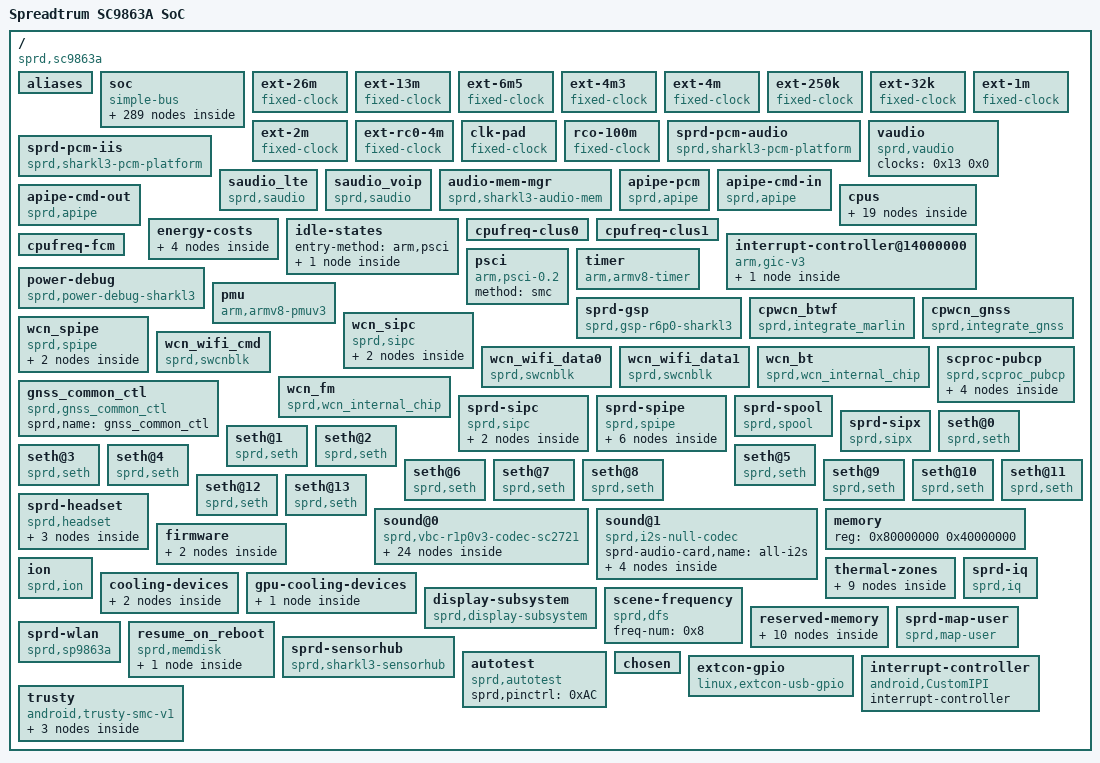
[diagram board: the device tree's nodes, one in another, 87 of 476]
/dts-v1/;
// version: 17
// last_comp_version: 16
// boot_cpuid_phys: 0x0

/ {
    interrupt-parent = <0x1>;
    #address-cells = <0x1>;
    #size-cells = <0x1>;
    cpuinfo_hardware = "Unisoc SC9863a";
    model = "Spreadtrum SC9863A SoC";
    compatible = "sprd,sc9863a";
    sprd,sc-id = "sp9863a 1000 1000";
    aliases {
        i2c0 = "/soc/ap-apb/i2c@70500000";
        i2c1 = "/soc/ap-apb/i2c@70600000";
        i2c2 = "/soc/ap-apb/i2c@70700000";
        i2c3 = "/soc/ap-apb/i2c@70800000";
        i2c4 = "/soc/ap-apb/i2c@70900000";
        i2c5 = "/soc/ap-apb/i2c@71500000";
        i2c6 = "/soc/ap-apb/i2c@71600000";
        i2c7 = "/soc/aon/i2c@40080000";
        spi0 = "/soc/ap-apb/spi@70a00000";
        spi1 = "/soc/ap-apb/spi@70b00000";
        spi2 = "/soc/ap-apb/spi@70c00000";
        spi3 = "/soc/ap-apb/spi@71400000";
        seth0 = "/seth@0";
        seth1 = "/seth@1";
        seth2 = "/seth@2";
        seth3 = "/seth@3";
        seth4 = "/seth@4";
        seth5 = "/seth@5";
        seth6 = "/seth@6";
        seth7 = "/seth@7";
        seth8 = "/seth@8";
        seth9 = "/seth@9";
        seth10 = "/seth@10";
        seth11 = "/seth@11";
        seth12 = "/seth@12";
        seth13 = "/seth@13";
        cooling-device0 = "/cooling-devices/cluster0-cooling";
        cooling-device1 = "/cooling-devices/cluster1-cooling";
        gpu-cooling0 = "/gpu-cooling-devices/gpu-cooling0";
        thm-sensor11 = "/thermal-zones/cpu-thmzone";
        serial0 = "/soc/ap-apb/serial@70000000";
        serial1 = "/soc/ap-apb/serial@70100000";
    };
    soc {
        compatible = "simple-bus";
        #address-cells = <0x1>;
        #size-cells = <0x1>;
        ranges;
        phandle = <0xAF>;
        modem-dbg-log@1000c000 {
            compatible = "sprd,dbg-log-sharkl3";
            reg = <0x1000C000 0x4000>;
            sprd,syscon-aon-apb = <0x2>;
            sprd,syscon-dsi-apb = <0x3>;
            sprd,syscon-pll-apb = <0x4>;
            sprd,ch-name = "TRAINING", "WTL", "MDAR", "TPIU", "DBUS", "WCN";
            sprd,ch-index = <0xF 0x1 0x0 0x2 0x3 0x4>;
            sprd,dcfix;
            sprd,mm;
            status = "okay";
            clock-names = "serdes_eb", "src0", "src1", "src2";
            clocks = <0x5 0x68 0x6 0x0 0x6 0x18 0x6 0x14>;
            phandle = <0xB0>;
        };
        syscon@20e00000 {
            compatible = "syscon";
            #syscon-cells = <0x2>;
            reg = <0x20E00000 0x10000>;
            phandle = <0xE>;
        };
        syscon@300e0000 {
            compatible = "syscon";
            #syscon-cells = <0x2>;
            reg = <0x300E0000 0x10000>;
            phandle = <0x8D>;
        };
        syscon@300f0000 {
            compatible = "syscon";
            #syscon-cells = <0x2>;
            reg = <0x300F0000 0x10000>;
            phandle = <0x4F>;
        };
        mailbox@400a0000 {
            compatible = "sprd,mailbox";
            reg = <0x400A0000 0x8000 0x400A8000 0x8000>;
            syscons = <0x2 0x4 0x200000>;
            syscon-names = "clk";
            interrupts = <0x0 0x44 0x4 0x0 0x45 0x4 0x0 0x77 0x4>;
            sprd,sensor = <0x7>;
            sprd,core-cnt = <0x8>;
            sprd,version = <0x102>;
            phandle = <0xB1>;
        };
        syscon@40200000 {
            compatible = "syscon";
            #syscon-cells = <0x2>;
            reg = <0x40200000 0x10000>;
            phandle = <0xB2>;
        };
        syscon@402b0000 {
            compatible = "syscon";
            #syscon-cells = <0x2>;
            reg = <0x402B0000 0x10000>;
            phandle = <0x7>;
        };
        power-domain@402b0058 {
            compatible = "sprd,sharkl3-disp-domain";
            reg = <0x402B0058 0x20>;
            syscons = <0x7 0x58 0x2000000>;
            syscon-names = "power";
            #power-domain-cells = <0x0>;
            phandle = <0x3B>;
        };
        syscon@402e0000 {
            compatible = "syscon";
            #syscon-cells = <0x2>;
            reg = <0x402E0000 0x10000>;
            phandle = <0x2>;
        };
        syscon@40350000 {
            compatible = "syscon";
            #syscon-cells = <0x2>;
            reg = <0x40350000 0x3000>;
            phandle = <0x3>;
        };
        syscon@40353000 {
            compatible = "syscon";
            #syscon-cells = <0x2>;
            reg = <0x40353000 0x6000>;
            phandle = <0x4>;
        };
        syscon@40359000 {
            compatible = "syscon";
            #syscon-cells = <0x2>;
            reg = <0x40359000 0x3000>;
            phandle = <0xF>;
        };
        syscon@4035c000 {
            compatible = "syscon";
            #syscon-cells = <0x2>;
            reg = <0x4035C000 0x3000>;
            phandle = <0x51>;
        };
        syscon@40363000 {
            compatible = "syscon";
            #syscon-cells = <0x2>;
            reg = <0x40363000 0x3000>;
            phandle = <0x17>;
        };
        syscon@40366000 {
            compatible = "syscon";
            #syscon-cells = <0x2>;
            reg = <0x40366000 0x3000>;
            phandle = <0x8E>;
        };
        syscon@403a0000 {
            compatible = "syscon";
            #syscon-cells = <0x2>;
            reg = <0x403A0000 0x10000>;
            phandle = <0x8F>;
        };
        syscon@60800000 {
            compatible = "syscon";
            #syscon-cells = <0x2>;
            reg = <0x60800000 0x10000>;
            phandle = <0x47>;
        };
        syscon@62000000 {
            compatible = "syscon";
            #syscon-cells = <0x2>;
            reg = <0x62000000 0x10000>;
            phandle = <0x3E>;
        };
        syscon@71300000 {
            compatible = "syscon";
            #syscon-cells = <0x2>;
            reg = <0x71300000 0x40000>;
            phandle = <0xB>;
        };
        syscon@40500000 {
            compatible = "syscon";
            #syscon-cells = <0x2>;
            reg = <0x40500000 0x10000>;
            phandle = <0x86>;
        };
        syscon@40510000 {
            compatible = "syscon";
            #syscon-cells = <0x2>;
            reg = <0x40510000 0x10000>;
            phandle = <0x87>;
        };
        syscon@40520000 {
            compatible = "syscon";
            #syscon-cells = <0x2>;
            reg = <0x40520000 0x10000>;
            phandle = <0x88>;
        };
        syscon@40530000 {
            compatible = "syscon";
            #syscon-cells = <0x2>;
            reg = <0x40530000 0x10000>;
            phandle = <0x89>;
        };
        syscon@40540000 {
            compatible = "syscon";
            #syscon-cells = <0x2>;
            reg = <0x40540000 0x10000>;
            phandle = <0x8A>;
        };
        syscon@40550000 {
            compatible = "syscon";
            #syscon-cells = <0x2>;
            reg = <0x40550000 0x10000>;
            phandle = <0x8B>;
        };
        ap-apb {
            compatible = "simple-bus";
            #address-cells = <0x1>;
            #size-cells = <0x1>;
            ranges;
            serial@70000000 {
                compatible = "sprd,sc9863-uart", "sprd,sc9836-uart";
                reg = <0x70000000 0x100>;
                interrupts = <0x0 0x2 0x4>;
                clock-names = "enable", "uart", "source";
                clocks = <0x8 0xC 0x9 0x9 0xA>;
                status = "okay";
                phandle = <0xB3>;
            };
            serial@70100000 {
                compatible = "sprd,sc9863-uart", "sprd,sc9836-uart";
                reg = <0x70100000 0x100>;
                interrupts = <0x0 0x3 0x4>;
                clock-names = "enable", "uart", "source";
                clocks = <0x8 0xD 0x9 0xA 0xA>;
                status = "okay";
                phandle = <0xB4>;
            };
            serial@70200000 {
                compatible = "sprd,sc9863-uart", "sprd,sc9836-uart";
                reg = <0x70200000 0x100>;
                interrupts = <0x0 0x4 0x4>;
                clock-names = "enable", "uart", "source";
                clocks = <0x8 0xE 0x9 0xB 0xA>;
                status = "disabled";
                phandle = <0xB5>;
            };
            serial@70300000 {
                compatible = "sprd,sc9863-uart", "sprd,sc9836-uart";
                reg = <0x70300000 0x100>;
                interrupts = <0x0 0x5 0x4>;
                clock-names = "enable", "uart", "source";
                clocks = <0x8 0xF 0x9 0xC 0xA>;
                status = "disabled";
                phandle = <0xB6>;
            };
            serial@70400000 {
                compatible = "sprd,sc9863-uart", "sprd,sc9836-uart";
                reg = <0x70400000 0x100>;
                interrupts = <0x0 0x6 0x4>;
                clock-names = "enable", "uart", "source";
                clocks = <0x8 0x10 0x9 0xD 0xA>;
                status = "disabled";
                phandle = <0xB7>;
            };
            i2c@70500000 {
                compatible = "sprd,sharkl3-i2c";
                reg = <0x70500000 0x1000>;
                interrupts = <0x0 0xB 0x4>;
                clock-names = "enable", "i2c", "source";
                clock-frequency = <0x186A0>;
                #address-cells = <0x1>;
                #size-cells = <0x0>;
                status = "disabled";
                clocks = <0x8 0x7 0x9 0xE 0xA>;
                phandle = <0xB8>;
            };
            i2c@70600000 {
                compatible = "sprd,sharkl3-i2c";
                reg = <0x70600000 0x1000>;
                interrupts = <0x0 0xC 0x4>;
                clock-names = "enable", "i2c", "source";
                clock-frequency = <0x186A0>;
                #address-cells = <0x1>;
                #size-cells = <0x0>;
                status = "disabled";
                clocks = <0x8 0x8 0x9 0xF 0xA>;
                phandle = <0xB9>;
            };
            i2c@70700000 {
                compatible = "sprd,sharkl3-i2c";
                reg = <0x70700000 0x1000>;
                interrupts = <0x0 0xD 0x4>;
                clock-names = "enable", "i2c", "source";
                clock-frequency = <0x186A0>;
                #address-cells = <0x1>;
                #size-cells = <0x0>;
                status = "disabled";
                clocks = <0x8 0x9 0x9 0x10 0xA>;
                phandle = <0xBA>;
            };
            i2c@70800000 {
                compatible = "sprd,sharkl3-i2c";
                reg = <0x70800000 0x1000>;
                interrupts = <0x0 0xE 0x4>;
                clock-names = "enable", "i2c", "source";
                clock-frequency = <0x61A80>;
                #address-cells = <0x1>;
                #size-cells = <0x0>;
                status = "disabled";
                clocks = <0x8 0xA 0x9 0x11 0xA>;
                phandle = <0xBB>;
            };
            i2c@70900000 {
                compatible = "sprd,sharkl3-i2c";
                reg = <0x70900000 0x1000>;
                interrupts = <0x0 0xF 0x4>;
                clock-names = "enable", "i2c", "source";
                clock-frequency = <0x186A0>;
                #address-cells = <0x1>;
                #size-cells = <0x0>;
                status = "disabled";
                clocks = <0x8 0xB 0x9 0x12 0xA>;
                phandle = <0xBC>;
            };
            spi@70a00000 {
                compatible = "sprd,sc9863-spi";
                reg = <0x70A00000 0x1000>;
                interrupts = <0x0 0x7 0x4>;
                #address-cells = <0x1>;
                #size-cells = <0x0>;
                status = "okay";
                clock-names = "enable", "spi", "source";
                clocks = <0x8 0x4 0x9 0x15 0x6 0x3>;
                phandle = <0xBD>;
            };
            spi@70b00000 {
                compatible = "sprd,sc9863-spi";
                reg = <0x70B00000 0x1000>;
                interrupts = <0x0 0x8 0x4>;
                #address-cells = <0x1>;
                #size-cells = <0x0>;
                status = "disabled";
                clock-names = "enable", "spi", "source";
                clocks = <0x8 0x5 0x9 0x16 0x6 0x3>;
                phandle = <0xBE>;
            };
            spi@70c00000 {
                compatible = "sprd,sc9863-spi";
                reg = <0x70C00000 0x1000>;
                interrupts = <0x0 0x9 0x4>;
                #address-cells = <0x1>;
                #size-cells = <0x0>;
                status = "disabled";
                clock-names = "enable", "spi", "source";
                clocks = <0x8 0x6 0x9 0x17 0x6 0x3>;
                phandle = <0xBF>;
            };
            i2s@70d00000 {
                compatible = "sprd,i2s";
                reg = <0x70D00000 0x100000>;
                sprd,dai_name = "i2s_bt_sco0";
                sprd,hw_port = <0x0>;
                sprd,syscon-ap-apb = <0xB>;
                #sound-dai-cells = <0x0>;
                status = "okay";
                clock-names = "clk_iis0", "clk_twpll_128m", "clk_twpll_153m6";
                clocks = <0x9 0x19 0x6 0xA 0x6 0xF>;
                sprd,config_type = "pcm";
                sprd,slave_timeout = <0xF11>;
                sprd,_hw_port = <0x0>;
                sprd,fs = <0x1F40>;
                sprd,bus_type = <0x1>;
                sprd,rtx_mode = <0x3>;
                sprd,byte_per_chan = <0x1>;
                sprd,slave_mode = <0x0>;
                sprd,lsb = <0x0>;
                sprd,lrck = <0x0>;
                sprd,low_for_left = <0x1>;
                sprd,clk_inv = <0x0>;
                sprd,pcm_short_frame = <0x1>;
                sprd,pcm_slot = <0x1>;
                sprd,pcm_cycle = <0x1>;
                sprd,tx_watermark = <0xC>;
                sprd,rx_watermark = <0x14>;
                phandle = <0xA2>;
            };
            spi@71400000 {
                compatible = "sprd,sc9863-spi";
                reg = <0x71400000 0x1000>;
                interrupts = <0x0 0x13 0x4>;
                #address-cells = <0x1>;
                #size-cells = <0x0>;
                status = "disabled";
                clock-names = "enable", "spi", "source";
                clocks = <0x8 0x12 0x9 0x18 0x6 0x3>;
                phandle = <0xC0>;
            };
            i2c@71500000 {
                compatible = "sprd,sharkl3-i2c";
                reg = <0x71500000 0x1000>;
                interrupts = <0x0 0x74 0x4>;
                clock-names = "enable", "i2c", "source";
                clock-frequency = <0x186A0>;
                #address-cells = <0x1>;
                #size-cells = <0x0>;
                status = "disabled";
                clocks = <0x8 0x13 0x9 0x13 0xA>;
                phandle = <0xC1>;
            };
            i2c@71600000 {
                compatible = "sprd,sharkl3-i2c";
                reg = <0x71600000 0x1000>;
                interrupts = <0x0 0x75 0x4>;
                clock-names = "enable", "i2c", "source";
                clock-frequency = <0x186A0>;
                #address-cells = <0x1>;
                #size-cells = <0x0>;
                status = "disabled";
                clocks = <0x8 0x14 0x9 0x14 0xA>;
                phandle = <0xC2>;
            };
        };
        ap-ahb {
            compatible = "simple-bus";
            #address-cells = <0x1>;
            #size-cells = <0x1>;
            ranges;
            dma-controller@20100000 {
                compatible = "sprd,sharkl3-dma";
                reg = <0x20100000 0x4000>;
                interrupts = <0x0 0x32 0x4>;
                #dma-cells = <0x1>;
                #dma-channels = <0x1C>;
                clock-names = "enable";
                clocks = <0xC 0x1>;
                phandle = <0x77>;
            };
            usb@20200000 {
                compatible = "sprd,sharkl3-musb";
                reg = <0x20200000 0x2000>;
                interrupts = <0x0 0x37 0x4>;
                interrupt-names = "mc";
                clocks = <0xC 0x0>;
                clock-names = "core_clk";
                phy-type = "usb20_sprd_phy";
                usb-phy = <0xD>;
                phy-names = "usb";
                dr-mode = "peripheral";
                phandle = <0xC3>;
            };
            hsphy@20e00000 {
                compatible = "sprd,sharkl3-phy";
                reg = <0x20E00000 0x3030>;
                reg-names = "phy_glb_regs";
                sprd,syscon-enable = <0x2>;
                sprd,syscon-apahb = <0xE>;
                sprd,syscon-anag4 = <0xF>;
                sprd,vdd-voltage = <0x325AA0>;
                #phy-cells = <0x0>;
                vdd-supply = <0x10>;
                extcon = <0x11>;
                phandle = <0xD>;
            };
            sdio@20600000 {
                compatible = "sprd,sdhc-r11p1";
                reg = <0x20600000 0x1000>;
                interrupts = <0x0 0x3C 0x4>;
                status = "okay";
                clock-names = "sdio_clk", "sdio_clk_source", "sdio_ahb_enable";
                clocks = <0x12 0x21 0x13 0x2 0xC 0x7>;
                sprd,hs400es-dly = <0x55 0x7F 0x38 0x38>;
                sprd,hs400-dly = <0x55 0xD3 0x35 0x35>;
                sprd,hs200-dly = <0x7F 0xCD 0xCD 0xCD>;
                sprd,ddr52-dly = <0x32 0x23 0x18 0x18>;
                vmmc-supply = <0x14>;
                voltage-ranges = <0xBB8 0xBB8>;
                bus-width = <0x8>;
                non-removable;
                cap-mmc-hw-reset;
                mmc-hs400-enhanced-strobe;
                mmc-hs400-1_8v;
                mmc-hs200-1_8v;
                mmc-ddr-1_8v;
                sprd,name = "sdio_emmc";
                sprd,sdio-adma;
                no-sdio;
                no-sd;
                phandle = <0xC4>;
            };
            sdio@20300000 {
                compatible = "sprd,sdhc-r11p1";
                reg = <0x20300000 0x1000>;
                interrupts = <0x0 0x39 0x4>;
                status = "okay";
                clock-names = "sdio_clk", "sdio_clk_source", "sdio_ahb_enable";
                clocks = <0x12 0x1E 0x13 0x2 0xC 0x4>;
                sprd,sdr104-dly = <0x7F 0xD1 0xD1 0xD1>;
                sprd,sdr50-dly = <0x7F 0xFF 0xFF 0xFF>;
                sprd,sdhs-dly = <0x7F 0x23 0x22 0x22>;
                vmmc-supply = <0x15>;
                vqmmc-supply = <0x16>;
                voltage-ranges = <0xBB8 0xBB8>;
                bus-width = <0x4>;
                sd-uhs-sdr104;
                sd-uhs-sdr50;
                sprd,name = "sdio_sd";
                sprd,sdio-adma;
                no-sdio;
                no-mmc;
                phandle = <0xC5>;
            };
        };
        aon {
            compatible = "simple-bus";
            #address-cells = <0x1>;
            #size-cells = <0x1>;
            ranges;
            audio-codec@40000000 {
                compatible = "sprd,sharkl3-audio-codec";
                reg = <0x40000000 0x2000>;
                interrupts = <0x0 0x14 0x0>;
                sprd,syscon-aon-apb = <0x2>;
                sprd,anlg-phy-g-syscon = <0x17>;
                phandle = <0x39>;
            };
            vbc@40020000 {
                compatible = "sprd,vbc-r1p0v3";
                #sound-dai-cells = <0x1>;
                reg = <0x40020000 0x10000>;
                sprd,clk-stable = <0x402D0060 0x4>;
                sprd,syscon-aon-apb = <0x2>;
                sprd,syscon-pmu-apb = <0x7>;
                sprd,dynamic-eq-support = <0x0>;
                sprd,vbc-iis-lr-invert = <0x0 0x1 0x1>;
                sprd,vbc-use-dma-type = <0x0 0x0 0x0 0x0>;
                sprd,vbc-use-ad01-only = <0x1>;
                sprd,iis_bt_fm_loop = <0x3 0x4>;
                pinctrl-names = "vbc_iis1_0", "ap_iis0_0", "ap_iis1_0", "tgdsp_iis0_0", "tgdsp_iis1_0", "pubcp_iis0_0", "vbc_iis1_3", "ap_iis0_3", "tgdsp_iis0_3", "tgdsp_iis1_3", "pubcp_iis0_3", "wcn_iis0_3", "vbc_iis1_4", "ap_iis0_4", "tgdsp_iis0_4", "tgdsp_iis1_4", "pubcp_iis0_4", "wcn_iis0_4", "iis_bt_fm_loop_3_4_enable", "iis_bt_fm_loop_3_4_disable";
                pinctrl-0 = <0x18>;
                pinctrl-1 = <0x19>;
                pinctrl-2 = <0x1A>;
                pinctrl-3 = <0x1B>;
                pinctrl-4 = <0x1C>;
                pinctrl-5 = <0x1D>;
                pinctrl-6 = <0x1E>;
                pinctrl-7 = <0x1F>;
                pinctrl-8 = <0x20>;
                pinctrl-9 = <0x21>;
                pinctrl-10 = <0x22>;
                pinctrl-11 = <0x23>;
                pinctrl-12 = <0x24>;
                pinctrl-13 = <0x25>;
                pinctrl-14 = <0x26>;
                pinctrl-15 = <0x27>;
                pinctrl-16 = <0x28>;
                pinctrl-17 = <0x29>;
                pinctrl-18 = <0x2A>;
                pinctrl-19 = <0x2B>;
                phandle = <0x9E>;
            };
            dma-controller@40100000 {
                compatible = "sprd,sharkl3-dma";
                reg = <0x40100000 0x4000>;
                #dma-cells = <0x1>;
                #dma-channels = <0x9>;
                clock-names = "enable";
                clocks = <0x5 0x32>;
                phandle = <0x76>;
            };
            gpio@40210000 {
                compatible = "sprd,sharkl3-eic-debounce";
                reg = <0x40210000 0x80 0x40370000 0x80>;
                gpio-controller;
                #gpio-cells = <0x2>;
                interrupt-controller;
                #interrupt-cells = <0x2>;
                interrupts = <0x0 0x25 0x4>;
                phandle = <0xAD>;
            };
            gpio@40210080 {
                compatible = "sprd,sharkl3-eic-latch";
                reg = <0x40210080 0x20 0x40370080 0x20>;
                gpio-controller;
                #gpio-cells = <0x2>;
                interrupt-controller;
                #interrupt-cells = <0x2>;
                interrupts = <0x0 0x25 0x4>;
                phandle = <0xC6>;
            };
            gpio@402100a0 {
                compatible = "sprd,sharkl3-eic-async";
                reg = <0x402100A0 0x20 0x403700A0 0x20>;
                gpio-controller;
                #gpio-cells = <0x2>;
                interrupt-controller;
                #interrupt-cells = <0x2>;
                interrupts = <0x0 0x25 0x4>;
                phandle = <0xC7>;
            };
            gpio@402100c0 {
                compatible = "sprd,sharkl3-eic-sync";
                reg = <0x402100C0 0x20 0x403700C0 0x20>;
                gpio-controller;
                #gpio-cells = <0x2>;
                interrupt-controller;
                #interrupt-cells = <0x2>;
                interrupts = <0x0 0x25 0x4>;
                phandle = <0xC8>;
            };
            timer@40040000 {
                compatible = "sprd,sysfrt-timer";
                reg = <0x40040000 0x10>;
                clocks = <0x2C>;
                phandle = <0xC9>;
            };
            timer@40050000 {
                compatible = "sprd,sharkl3-timer";
                reg = <0x40050000 0x14>;
                interrupts = <0x0 0x1B 0x4>;
                clocks = <0x2C>;
            };
            timer@40050020 {
                compatible = "sprd,sharkl3-suspend-timer";
                reg = <0x40050020 0x14>;
                interrupts = <0x0 0x1C 0x4>;
                clocks = <0x2C>;
            };
            timer@40230000 {
                compatible = "sprd,syst-timer";
                reg = <0x40230000 0x10>;
                phandle = <0xCA>;
            };
            efuse@40240000 {
                compatible = "sprd,sharkl3-efuse";
                reg = <0x40240000 0x10000>;
                clock-names = "enable";
                hwlocks = <0x2D 0x8>;
                clocks = <0x5 0xD>;
                phandle = <0xCB>;
                gthm-delta@21 {
                    reg = <0x21 0x4>;
                    bits = <0x1 0x7>;
                    phandle = <0x2E>;
                };
                cthm-sign@22 {
                    reg = <0x22 0x4>;
                    bits = <0x0 0x1>;
                    phandle = <0x2F>;
                };
                cthm-ratio@22 {
                    reg = <0x22 0x4>;
                    bits = <0x1 0x7>;
                    phandle = <0x30>;
                };
                cthm-delta@23 {
                    reg = <0x23 0x4>;
                    bits = <0x0 0x7>;
                    phandle = <0x31>;
                };
                wcn-alpha@14 {
                    reg = <0x14 0x4>;
                    phandle = <0x93>;
                };
                wcn-beta@18 {
                    reg = <0x18 0x4>;
                    phandle = <0x94>;
                };
                wcn-gamma@1c {
                    reg = <0x1C 0x4>;
                    phandle = <0x95>;
                };
                wcn-delta@20 {
                    reg = <0x20 0x4>;
                    phandle = <0x96>;
                };
                dvfs-bin-dsu@a {
                    reg = <0xA 0x4>;
                    bits = <0x4 0x4>;
                    phandle = <0x85>;
                };
                dvfs-bin-cpu0@9 {
                    reg = <0x9 0x4>;
                    bits = <0x0 0x4>;
                    phandle = <0x81>;
                };
                dvfs-bin-cpu1@9 {
                    reg = <0x9 0x4>;
                    bits = <0x4 0x4>;
                    phandle = <0x83>;
                };
            };
            pwm@40260000 {
                compatible = "sprd,sharkl3-pwm", "sprd,sharkl5-pwm";
                reg = <0x40260000 0x10000>;
                clock-names = "clk_parent", "clk_pwm0", "clk_pwm0_eb", "clk_pwm1", "clk_pwm1_eb", "clk_pwm2", "clk_pwm2_eb";
                clocks = <0xA 0x12 0xF 0x5 0x4 0x12 0x10 0x5 0x5 0x12 0x11 0x5 0x6>;
                #pwm-cells = <0x2>;
                phandle = <0xCC>;
            };
            pinctrl@402a0000 {
                compatible = "sprd,sharkl3-pinctrl";
                reg = <0x402A0000 0x10000>;
                phandle = <0xAC>;
                iismtx-inf0-8 {
                    pins = "SHARKL3_IIS_INF0_SYS_SEL";
                    sprd,control = <0x8>;
                    phandle = <0x18>;
                };
                iismtx-inf0-0 {
                    pins = "SHARKL3_IIS_INF0_SYS_SEL";
                    sprd,control = <0x0>;
                    phandle = <0x19>;
                };
                iismtx-inf0-1 {
                    pins = "SHARKL3_IIS_INF0_SYS_SEL";
                    sprd,control = <0x1>;
                    phandle = <0x1A>;
                };
                iismtx-inf0-4 {
                    pins = "SHARKL3_IIS_INF0_SYS_SEL";
                    sprd,control = <0x4>;
                    phandle = <0x1B>;
                };
                iismtx-inf0-5 {
                    pins = "SHARKL3_IIS_INF0_SYS_SEL";
                    sprd,control = <0x5>;
                    phandle = <0x1C>;
                };
                iismtx-inf0-3 {
                    pins = "SHARKL3_IIS_INF0_SYS_SEL";
                    sprd,control = <0x3>;
                    phandle = <0x1D>;
                };
                iismtx-inf3-8 {
                    pins = "SHARKL3_IIS_INF3_SYS_SEL";
                    sprd,control = <0x8>;
                    phandle = <0x1E>;
                };
                iismtx-inf3-0 {
                    pins = "SHARKL3_IIS_INF3_SYS_SEL";
                    sprd,control = <0x0>;
                    phandle = <0x1F>;
                };
                iismtx-inf3-4 {
                    pins = "SHARKL3_IIS_INF3_SYS_SEL";
                    sprd,control = <0x4>;
                    phandle = <0x20>;
                };
                iismtx-inf3-5 {
                    pins = "SHARKL3_IIS_INF3_SYS_SEL";
                    sprd,control = <0x5>;
                    phandle = <0x21>;
                };
                iismtx-inf3-3 {
                    pins = "SHARKL3_IIS_INF3_SYS_SEL";
                    sprd,control = <0x3>;
                    phandle = <0x22>;
                };
                iismtx-inf3-11 {
                    pins = "SHARKL3_IIS_INF3_SYS_SEL";
                    sprd,control = <0xB>;
                    phandle = <0x23>;
                };
                iismtx-inf4-8 {
                    pins = "SHARKL3_IIS_INF4_SYS_SEL";
                    sprd,control = <0x8>;
                    phandle = <0x24>;
                };
                iismtx-inf4-0 {
                    pins = "SHARKL3_IIS_INF4_SYS_SEL";
                    sprd,control = <0x0>;
                    phandle = <0x25>;
                };
                iismtx-inf4-4 {
                    pins = "SHARKL3_IIS_INF4_SYS_SEL";
                    sprd,control = <0x4>;
                    phandle = <0x26>;
                };
                iismtx-inf4-5 {
                    pins = "SHARKL3_IIS_INF4_SYS_SEL";
                    sprd,control = <0x5>;
                    phandle = <0x27>;
                };
                iismtx-inf4-3 {
                    pins = "SHARKL3_IIS_INF4_SYS_SEL";
                    sprd,control = <0x3>;
                    phandle = <0x28>;
                };
                iismtx-inf4-11 {
                    pins = "SHARKL3_IIS_INF4_SYS_SEL";
                    sprd,control = <0xB>;
                    phandle = <0x29>;
                };
                iismtx-inf3-inf4-loop-1 {
                    pins = "SHARKL3_IIS_INF4_INF3_LOOP";
                    sprd,control = <0x1>;
                    phandle = <0x2A>;
                };
                iismtx-inf3-inf4-loop-0 {
                    pins = "SHARKL3_IIS_INF4_INF3_LOOP";
                    sprd,control = <0x0>;
                    phandle = <0x2B>;
                };
            };
            gpio-controller@402c0000 {
                compatible = "sprd,sharkl3-gpio-plus";
                reg = <0x402C0000 0x1000>;
                gpio-controller;
                #gpio-cells = <0x2>;
                interrupt-controller;
                #interrupt-cells = <0x2>;
                interrupts = <0x0 0x82 0x4>;
                phandle = <0x9C>;
            };
            gpu-thm@402f0000 {
                compatible = "sprd,sharkl3-thermal";
                reg = <0x402F0000 0x10000>;
                clock-names = "enable";
                clocks = <0x5 0x20>;
                #thermal-sensor-cells = <0x1>;
                sprd,algor_ver = <0x2>;
                nvmem-cells = <0x2E>;
                nvmem-cell-names = "thm_delta_cal";
                phandle = <0xA7>;
            };
            cpu-thm@40390000 {
                compatible = "sprd,sharkl3-thermal";
                reg = <0x40390000 0x10000>;
                clock-names = "enable";
                clocks = <0x5 0x20>;
                #thermal-sensor-cells = <0x1>;
                sprd,algor_ver = <0x1>;
                nvmem-cells = <0x2F 0x30 0x31>;
                nvmem-cell-names = "thm_sign_cal", "thm_ratio_cal", "thm_delta_cal";
                phandle = <0xA3>;
            };
            hwspinlock@40060000 {
                compatible = "sprd,hwspinlock-r3p0";
                reg = <0x40060000 0x10000>;
                #hwlock-cells = <0x1>;
                clock-names = "enable";
                clocks = <0x5 0x16>;
                phandle = <0x2D>;
            };
            i2c@40080000 {
                compatible = "sprd,sharkl3-hw-i2c";
                reg = <0x40080000 0x1000>;
                interrupts = <0x0 0x22 0x4>;
                clock-names = "enable", "i2c", "source", "clk_hw_i2c";
                clock-frequency = <0x186A0>;
                #address-cells = <0x1>;
                #size-cells = <0x0>;
                status = "disabled";
                phandle = <0xCD>;
                regulator@60 {
                    compatible = "fcs,fan53555";
                    reg = <0x60>;
                    regulator-name = "fan53555";
                    regulator-min-microvolt = <0x93378>;
                    regulator-max-microvolt = <0x1587B8>;
                    regulator-ramp-delay = <0xFA00>;
                    regulator-always-on;
                    fcs,suspend-voltage-selector = <0x1>;
                    phandle = <0x78>;
                };
            };
            hwdvfs@40300000 {
                compatible = "sprd,sharkl3-hwdvfs";
                sprd,syscon-enable = <0x2>;
                sprd,anlg-phy-g4-ctrl = <0xF>;
                reg = <0x40300000 0x1000>;
                interrupts = <0x0 0x79 0x4>;
                phandle = <0xCE>;
            };
            sprd-swdvfs {
                compatible = "sprd,sharkl3-swdvfs";
                phandle = <0xCF>;
            };
            watchdog@40310000 {
                compatible = "sprd,wdt-r2p0-fiq-sharkl3";
                reg = <0x40310000 0x1000>;
                interrupts = <0x0 0x7C 0x4>;
                timeout-sec = <0x1E>;
                clock-names = "enable", "rtc_enable";
                clocks = <0x5 0x26 0x5 0x42>;
            };
            djtag@40340000 {
                compatible = "sprd,djtag";
                reg = <0x40340000 0x1000>;
                syscon-names = "soft_rst";
                syscons = <0x2 0x130 0x80>;
                clock-names = "enable", "tck";
                clocks = <0x5 0x30 0x5 0x29>;
                hwlocks = <0x2D 0xA>;
                hwlock-names = "djtag";
                #address-cells = <0x1>;
                #size-cells = <0x0>;
                phandle = <0xD0>;
                aon-busmonitor@3 {
                    compatible = "sprd,sharkl3-busmonitor";
                    interrupts = <0x0 0x5C 0x4>;
                    reg = <0x3>;
                    sprd,bm-num = <0x7>;
                    sprd,bm-name = "AP", "WTLCP", "PUBCP", "SP", "DMA", "EAXI", "WCN";
                    sprd,bm-type = <0x1 0x1 0x1 0x1 0x1 0x1 0x1>;
                    sprd,bm-dap = <0x0 0x2 0x1 0x3 0x4 0x5 0x9>;
                    sprd,bm-config = <0x0 0x1 0x1 0x0 0x1 0x1 0x0 0x1 0x1 0x0 0x1 0x1 0x0 0x1 0x1 0x0 0x1 0x1 0x0 0x1 0x1>;
                    sprd,bm-id = <0x0 0x0 0x0 0x0 0x0 0x0 0x0 0x0 0x0 0x0 0x0 0x0 0x0 0x0 0x0 0x0 0x0 0x0 0x0 0x0 0x0>;
                    sprd,bm-ranges = <0x0 0x0 0x0 0x0 0x0 0x0 0x0 0x0 0x0 0x0 0x0 0x0 0x0 0x0>;
                };
                apcpu-busmonitor@7 {
                    compatible = "sprd,sharkl3-busmonitor";
                    interrupts = <0x0 0x57 0x4>;
                    reg = <0x7>;
                    sprd,bm-num = <0x2>;
                    sprd,bm-name = "ACE", "AP";
                    sprd,bm-type = <0x1 0x1>;
                    sprd,bm-dap = <0x1 0x2>;
                    sprd,bm-config = <0x0 0x1 0x1 0x0 0x1 0x1>;
                    sprd,bm-id = <0x0 0x0 0x0 0x0 0x0 0x0>;
                    sprd,bm-ranges = <0x0 0x0 0x0 0x0>;
                };
            };
            spi@41800000 {
                compatible = "sprd,sharkl3-adi";
                reg = <0x41800000 0x200000>;
                #address-cells = <0x1>;
                #size-cells = <0x0>;
                sprd,hw-channels = <0x21 0x8C20 0x23 0x8CC4 0x24 0x8CD0 0x13 0x8C44 0x14 0x8C44 0x15 0x8C44 0x16 0x8C44>;
                phandle = <0xD1>;
                pmic@0 {
                    compatible = "sprd,sc2721";
                    reg = <0x0>;
                    spi-max-frequency = <0x18CBA80>;
                    interrupts = <0x0 0x26 0x4>;
                    interrupt-controller;
                    #interrupt-cells = <0x2>;
                    #address-cells = <0x1>;
                    #size-cells = <0x0>;
                    phandle = <0x32>;
                    watchdog@40 {
                        compatible = "sprd,sc2721-wdt", "sprd,sc27xx-wdt";
                        reg = <0x40>;
                        phandle = <0xD2>;
                    };
                    led-controller@180 {
                        compatible = "sprd,sc27xx-bltc", "sprd,sc2721-bltc";
                        #address-cells = <0x1>;
                        #size-cells = <0x0>;
                        reg = <0x180>;
                        led@0 {
                            label = "red";
                            reg = <0x0>;
                        };
                        led@1 {
                            label = "green";
                            reg = <0x1>;
                        };
                        led@2 {
                            label = "blue";
                            reg = <0x2>;
                        };
                    };
                    rtc@200 {
                        compatible = "sprd,sc27xx-rtc", "sprd,sc2721-rtc";
                        reg = <0x200>;
                        interrupt-parent = <0x32>;
                        interrupts = <0x1 0x4>;
                    };
                    gpio-controller@280 {
                        compatible = "sprd,sc27xx-eic", "sprd,sc2721-eic";
                        reg = <0x280>;
                        interrupts = <0x4 0x4>;
                        interrupt-parent = <0x32>;
                        gpio-controller;
                        #gpio-cells = <0x2>;
                        interrupt-controller;
                        #interrupt-cells = <0x2>;
                        phandle = <0x36>;
                    };
                    flash@2a8 {
                        compatible = "sprd,sc27xx-flash", "sprd,sc2721-flash";
                        torch-led-idx = <0x1>;
                        flash-idx = <0x1>;
                        reg = <0x2A8>;
                        status = "okay";
                        phandle = <0xD3>;
                    };
                    efuse@300 {
                        compatible = "sprd,sc27xx-efuse", "sprd,sc2721-efuse";
                        reg = <0x300>;
                        #address-cells = <0x1>;
                        #size-cells = <0x1>;
                        hwlocks = <0x2D 0xC>;
                        calib@6 {
                            reg = <0x6 0x2>;
                            phandle = <0x37>;
                        };
                        calib@24 {
                            reg = <0x24 0x2>;
                            phandle = <0x34>;
                        };
                        calib@26 {
                            reg = <0x26 0x2>;
                            phandle = <0x35>;
                        };
                        calib@1a {
                            reg = <0x1A 0x2>;
                            phandle = <0x33>;
                        };
                        calib@0 {
                            reg = <0x0 0x2>;
                            phandle = <0x98>;
                        };
                        calib@28 {
                            reg = <0x28 0x2>;
                            phandle = <0x99>;
                        };
                        calib@2c {
                            reg = <0x2C 0x2>;
                            phandle = <0x9A>;
                        };
                    };
                    typec@380 {
                        compatible = "sprd,sc27xx-typec", "sprd,sc2721-typec";
                        interrupt-parent = <0x32>;
                        interrupts = <0xA 0x4>;
                        reg = <0x380>;
                        mode = <0x2>;
                        nvmem-cells = <0x33>;
                        nvmem-cell-names = "cc_calib";
                        status = "okay";
                        phandle = <0xD4>;
                    };
                    adc@400 {
                        compatible = "sprd,sc27xx-adc", "sprd,sc2721-adc";
                        reg = <0x400>;
                        interrupt-parent = <0x32>;
                        interrupts = <0x0 0x4>;
                        #io-channel-cells = <0x1>;
                        hwlocks = <0x2D 0x4>;
                        nvmem-cells = <0x34 0x35>;
                        nvmem-cell-names = "big_scale_calib", "small_scale_calib";
                        phandle = <0x38>;
                    };
                    fgu@a00 {
                        compatible = "sprd,sc27xx-fgu", "sprd,sc2731-fgu";
                        reg = <0xA00>;
                        bat-detect-gpio = <0x36 0x9 0x0>;
                        nvmem-cell-names = "fgu_calib";
                        nvmem-cells = <0x37>;
                        io-channels = <0x38 0x0 0x38 0xE 0x38 0x4>;
                        io-channel-names = "bat-temp", "charge-vol", "batt_id-vol";
                        interrupt-parent = <0x32>;
                        interrupts = <0x3 0x4>;
                        phandle = <0xD5>;
                    };
                    syscon@c00 {
                        compatible = "sprd,sc27xx-syscon";
                        reg = <0xC00 0xECC 0xEC0>;
                    };
                    audio-codec@700 {
                        compatible = "sprd,sc2721-audio-codec", "sprd,sc27xx-audio-codec";
                        #sound-dai-cells = <0x1>;
                        reg = <0x700>;
                        interrupts = <0x6 0x0>;
                        sprd,syscon-pmu-apb = <0x7>;
                        status = "okay";
                        digital-codec = <0x39>;
                        phandle = <0x9F>;
                    };
                    power-controller@c00 {
                        compatible = "sprd,sc27xx-regulator", "sprd,sc2721-regulator";
                        DCDC_CPU {
                            regulator-name = "vddcpu";
                            regulator-min-microvolt = <0x61A80>;
                            regulator-max-microvolt = <0x1E74E0>;
                            regulator-ramp-delay = <0x61A8>;
                            regulator-always-on;
                            phandle = <0x7D>;
                        };
                        DCDC_CORE {
                            regulator-name = "vddcore";
                            regulator-min-microvolt = <0x61A80>;
                            regulator-max-microvolt = <0x1E74E0>;
                            regulator-ramp-delay = <0x61A8>;
                            regulator-always-on;
                            phandle = <0xD6>;
                        };
                        DCDC_MEM {
                            regulator-name = "vddmem";
                            regulator-min-microvolt = <0x61A80>;
                            regulator-max-microvolt = <0x36E24B>;
                            regulator-ramp-delay = <0x61A8>;
                            regulator-always-on;
                            phandle = <0xD7>;
                        };
                        DCDC_GEN {
                            regulator-name = "vddgen";
                            regulator-min-microvolt = <0x927C0>;
                            regulator-max-microvolt = <0x39EF8B>;
                            regulator-ramp-delay = <0x61A8>;
                            regulator-always-on;
                            phandle = <0xD8>;
                        };
                        LDO_VDDCAMA {
                            regulator-name = "vddcama";
                            regulator-min-microvolt = <0x124F80>;
                            regulator-max-microvolt = <0x393870>;
                            regulator-ramp-delay = <0x61A8>;
                            phandle = <0xD9>;
                        };
                        LDO_VDDCAMMOT {
                            regulator-name = "vddcammot";
                            regulator-min-microvolt = <0x124F80>;
                            regulator-max-microvolt = <0x393870>;
                            regulator-ramp-delay = <0x61A8>;
                            phandle = <0xDA>;
                        };
                        LDO_VDDSIM2 {
                            regulator-name = "vddsim2";
                            regulator-min-microvolt = <0x124F80>;
                            regulator-max-microvolt = <0x393870>;
                            regulator-ramp-delay = <0x61A8>;
                            phandle = <0xDB>;
                        };
                        LDO_VDDEMMCCORE {
                            regulator-name = "vddemmccore";
                            regulator-min-microvolt = <0x124F80>;
                            regulator-max-microvolt = <0x393870>;
                            regulator-ramp-delay = <0x61A8>;
                            phandle = <0x14>;
                        };
                        LDO_VDDSDCORE {
                            regulator-name = "vddsdcore";
                            regulator-min-microvolt = <0x124F80>;
                            regulator-max-microvolt = <0x393870>;
                            regulator-ramp-delay = <0x61A8>;
                            phandle = <0x15>;
                        };
                        LDO_VDDSDIO {
                            regulator-name = "vddsdio";
                            regulator-min-microvolt = <0x124F80>;
                            regulator-max-microvolt = <0x393870>;
                            regulator-ramp-delay = <0x61A8>;
                            phandle = <0x16>;
                        };
                        LDO_VDD28 {
                            regulator-name = "vdd28";
                            regulator-min-microvolt = <0x124F80>;
                            regulator-max-microvolt = <0x393870>;
                            regulator-ramp-delay = <0x61A8>;
                            regulator-always-on;
                            phandle = <0xDC>;
                        };
                        LDO_VDDWIFIPA {
                            regulator-name = "vddwifipa";
                            regulator-min-microvolt = <0x124F80>;
                            regulator-max-microvolt = <0x393870>;
                            regulator-ramp-delay = <0x61A8>;
                            phandle = <0x92>;
                        };
                        LDO_VDD18_DCXO {
                            regulator-name = "vdd18_dcxo";
                            regulator-min-microvolt = <0x124F80>;
                            regulator-max-microvolt = <0x393870>;
                            regulator-ramp-delay = <0x61A8>;
                            regulator-always-on;
                            phandle = <0xDD>;
                        };
                        LDO_VDDUSB33 {
                            regulator-name = "vddusb33";
                            regulator-min-microvolt = <0x124F80>;
                            regulator-max-microvolt = <0x393870>;
                            regulator-ramp-delay = <0x61A8>;
                            phandle = <0x10>;
                        };
                        LDO_VDDCAMD {
                            regulator-name = "vddcamd";
                            regulator-min-microvolt = <0xF5AAA>;
                            regulator-max-microvolt = <0x16E360>;
                            regulator-ramp-delay = <0x61A8>;
                            phandle = <0xDE>;
                        };
                        LDO_VDDCON {
                            regulator-name = "vddcon";
                            regulator-min-microvolt = <0x10E14A>;
                            regulator-max-microvolt = <0x186A00>;
                            regulator-ramp-delay = <0x61A8>;
                            phandle = <0x91>;
                        };
                        LDO_VDDCAMIO {
                            regulator-name = "vddcamio";
                            regulator-min-microvolt = <0x10E14A>;
                            regulator-max-microvolt = <0x1CFDE0>;
                            regulator-ramp-delay = <0x61A8>;
                            phandle = <0xDF>;
                        };
                        LDO_VDD18 {
                            regulator-name = "vdd18";
                            regulator-min-microvolt = <0x10E14A>;
                            regulator-max-microvolt = <0x1CFDE0>;
                            regulator-ramp-delay = <0x61A8>;
                            phandle = <0xE0>;
                        };
                        LDO_VDDRF18 {
                            regulator-name = "vddrf18";
                            regulator-min-microvolt = <0x10E14A>;
                            regulator-max-microvolt = <0x1CFDE0>;
                            regulator-ramp-delay = <0x61A8>;
                            phandle = <0xE1>;
                        };
                        LDO_VDDRF125 {
                            regulator-name = "vddrf125";
                            regulator-min-microvolt = <0x10E14A>;
                            regulator-max-microvolt = <0x155CC0>;
                            regulator-ramp-delay = <0x61A8>;
                            phandle = <0xE2>;
                        };
                        LDO_VDDLDOMEM {
                            regulator-name = "vddldomem";
                            regulator-min-microvolt = <0x10E14A>;
                            regulator-max-microvolt = <0x155CC0>;
                            regulator-ramp-delay = <0x61A8>;
                            phandle = <0xE3>;
                        };
                        LDO_VDDKPLED {
                            regulator-name = "vddkpled";
                            regulator-min-microvolt = <0x124F80>;
                            regulator-max-microvolt = <0x393870>;
                            regulator-ramp-delay = <0x61A8>;
                            phandle = <0xE4>;
                        };
                    };
                    vibrator@eb4 {
                        compatible = "sprd,sc27xx-vibrator", "sprd,sc2721-vibrator";
                        reg = <0xEB4>;
                    };
                    poweroff@efc {
                        compatible = "sprd,sc27xx-poweroff", "sprd,sc2721-poweroff";
                        reg = <0xEFC>;
                    };
                    hw-reset@f1c {
                        compatible = "sprd,sc27xx-7sreset", "sprd,sc2721-7sreset";
                        reg = <0xF1C 0xEEC>;
                    };
                };
            };
        };
        mm {
            compatible = "simple-bus";
            #address-cells = <0x1>;
            #size-cells = <0x1>;
            ranges;
            cam-domain {
                compatible = "sprd,cam-domain";
                syscons = <0x7 0x1C 0x1000000 0x7 0x1C 0x2000000 0x7 0xBC 0xF8000000 0x7 0x6EC 0x80000 0x2 0x50 0x1F3F8>;
                syscon-names = "shutdown_en", "force_shutdown", "pwr_status0", "bus_status0", "init_dis_bits";
                clock-names = "clk_cphy_cfg_gate_eb", "clk_mm_eb", "clk_mm_ahb", "clk_mm_ahb_parent", "clk_mm_emc", "clk_mm_emc_parent";
                clocks = <0x5 0x66 0x5 0x19 0x12 0x2A 0x6 0xF 0x12 0x29 0x6 0x8>;
                phandle = <0xE5>;
            };
            gpu@60000000 {
                compatible = "sprd,rogue";
                reg = <0x60000000 0x100000>;
                syscons = <0x7 0x20 0x2000000 0x7 0x124 0x2000000 0x7 0x124 0x1000000>;
                syscon-names = "top_force_shutdown", "core_force_shutdown", "core_auto_shutdown";
                interrupts = <0x0 0x27 0x4>;
                operating-points = <0x3E800 0x0 0x5DC00 0x0 0x86470 0x0>;
                sprd,dvfs-lists = <0x3E800 0x0 0x5 0x1 0x5DC00 0x0 0x7 0x1 0x86470 0x0 0x9 0x1>;
                sprd,dvfs-default = <0x0>;
                sprd,dvfs-scene-extreme = <0x2>;
                sprd,dvfs-scene-high = <0x1>;
                sprd,dvfs-scene-medium = <0x1>;
                sprd,dvfs-scene-low = <0x0>;
                sprd,dvfs-range-max = <0x2>;
                sprd,dvfs-range-min = <0x0>;
                clocks = <0x5 0x4C 0x12 0x27 0x12 0x28 0x6 0xF 0x6 0x3 0x6 0x9 0x6 0xC 0x6 0x2 0x6 0x8 0x6 0x17>;
                phandle = <0xE6>;
            };
            dpu@63000000 {
                compatible = "sprd,display-processor";
                reg = <0x63000000 0x1000>;
                interrupts = <0x0 0x2E 0x4>;
                status = "okay";
                iommus = <0x3A>;
                power-domains = <0x3B>;
                dma-coherent;
                sprd,ip = "dpu-r2p0";
                sprd,soc = "sharkl3";
                sprd,logo-memory = <0x3C>;
                syscons = <0x2 0xC 0x100000>;
                syscon-names = "reset";
                clock-names = "clk_src_128m", "clk_src_153m6", "clk_src_192m", "clk_src_256m", "clk_src_384m", "clk_dpu_core", "clk_dpu_dpi", "clk_aon_apb_disp_eb";
                clocks = <0x6 0xA 0x6 0xF 0x6 0x3 0x6 0x9 0x6 0x2 0x12 0x22 0x12 0x23 0x5 0x4D>;
                phandle = <0xE7>;
                port {
                    phandle = <0xA8>;
                    endpoint {
                        remote-endpoint = <0x3D>;
                        phandle = <0x43>;
                    };
                };
            };
            gsp@63000000 {
                compatible = "sprd,gsp-core";
                reg = <0x63000000 0x2000>;
                core-id = <0x0>;
                kcfg-num = <0x10>;
                interrupts = <0x0 0x33 0x4>;
                iommus = <0x3A>;
                clock-names = "clk_dpu_core_src", "clk_dpu_core", "clk_aon_apb_disp_eb";
                clocks = <0x6 0x2 0x12 0x22 0x5 0x4D>;
                phandle = <0x8C>;
            };
            iommu@63000800 {
                compatible = "sprd,iommuex-dispc";
                reg = <0x63000800 0x80>;
                sprd,iova-base = <0x30000000>;
                sprd,iova-size = <0x10000000>;
                reg_name = "mmu_reg";
                status = "okay";
                #iommu-cells = <0x0>;
                phandle = <0x3A>;
            };
            video-codec@62200000 {
                compatible = "sprd,sharkl3-vsp";
                reg = <0x62200000 0xC000>;
                interrupts = <0x0 0x2B 0x4>;
                syscons = <0x3E 0x4 0xC 0x7 0x30 0x2000000 0x7 0x30 0x1000000 0x7 0x128 0x1F 0x2 0x4 0x4000>;
                syscon-names = "reset", "pmu_vsp_force_shutdown", "pmu_vsp_auto_shutdown", "pmu_pwr_status", "vsp_domain_eb";
                iommus = <0x3F>;
                status = "okay";
                clock-names = "clk_mm_eb", "clk_ahb_gate_vsp_eb", "clk_axi_gate_vsp", "clk_vsp_ahb_mmu_eb", "clk_ahb_vsp", "clk_ahb_vsp_parent", "clk_emc_vsp", "clk_emc_vsp_parent", "clk_src_76m8", "clk_src_128m", "clk_src_256m", "clk_src_307m2", "clk_src_384m", "clk_vsp";
                clocks = <0x5 0x2C 0x5 0x51 0x40 0x0 0x40 0x1 0x12 0x34 0x6 0xF 0x12 0x33 0x6 0x19 0x6 0x10 0x6 0xA 0x6 0x9 0x6 0xC 0x6 0x2 0x12 0x35>;
                phandle = <0xE8>;
            };
            iommu@62200000 {
                compatible = "sprd,iommuex-vsp";
                reg = <0x62200000 0x80>;
                sprd,iova-base = <0x20000000>;
                sprd,iova-size = <0x10000000>;
                reg_name = "mmu_reg";
                status = "okay";
                #iommu-cells = <0x0>;
                phandle = <0x3F>;
            };
            jpeg-codec@62300000 {
                compatible = "sprd,sharkl3-jpg";
                reg = <0x62300000 0x8000>;
                interrupts = <0x0 0x2A 0x4>;
                syscons = <0x3E 0x4 0x20 0x2 0x0 0x2000000>;
                syscon-names = "reset", "aon_apb_eb";
                iommus = <0x41>;
                status = "okay";
                clock-names = "jpg_domain_eb", "clk_aon_jpg_emc_eb", "jpg_dev_eb", "jpg_ckg_eb", "clk_ahb_vsp", "clk_ahb_vsp_parent", "clk_emc_vsp", "clk_emc_vsp_parent", "clk_src_256m", "clk_src_307m2", "jpg_clk";
                clocks = <0x5 0x2C 0x5 0x51 0x40 0x0 0x40 0x2 0x12 0x34 0x6 0xF 0x12 0x33 0x6 0x19 0x6 0x9 0x6 0xC 0x12 0x2E>;
                phandle = <0xE9>;
            };
            iommu@62300300 {
                compatible = "sprd,iommuex-jpg";
                reg = <0x62300300 0x400>;
                sprd,iova-base = <0x70000000>;
                sprd,iova-size = <0x10000000>;
                reg_name = "mmu_reg";
                status = "okay";
                #iommu-cells = <0x0>;
                phandle = <0x41>;
            };
            dsi@63100000 {
                compatible = "sprd,dsi-host";
                reg = <0x63100000 0x1000>;
                interrupts = <0x0 0x30 0x4 0x0 0x31 0x4>;
                status = "okay";
                power-domains = <0x3B>;
                sprd,ip = "sprd,dsi-ctrl", "r3p0";
                sprd,soc = "sharkl3";
                syscons = <0x2 0x628 0x4>;
                syscon-names = "reset";
                clock-names = "clk_aon_apb_disp_eb";
                clocks = <0x5 0x4D>;
                #address-cells = <0x1>;
                #size-cells = <0x0>;
                phandle = <0xEA>;
                ports {
                    #address-cells = <0x1>;
                    #size-cells = <0x0>;
                    port@0 {
                        reg = <0x0>;
                        endpoint {
                            remote-endpoint = <0x42>;
                            phandle = <0x46>;
                        };
                    };
                    port@1 {
                        reg = <0x1>;
                        endpoint {
                            remote-endpoint = <0x43>;
                            phandle = <0x3D>;
                        };
                    };
                };
                panel {
                    compatible = "sprd,generic-mipi-panel";
                    #address-cells = <0x1>;
                    #size-cells = <0x0>;
                    reg = <0x0>;
                    phandle = <0xEB>;
                    port@1 {
                        reg = <0x1>;
                        endpoint {
                            remote-endpoint = <0x44>;
                            phandle = <0x45>;
                        };
                    };
                };
            };
            dphy {
                compatible = "sprd,dsi-phy";
                #address-cells = <0x1>;
                #size-cells = <0x0>;
                reg = <0x63100000 0x1000>;
                status = "okay";
                sprd,ip = "sprd,megacores-sharkle";
                sprd,soc = "sharkl3";
                syscons = <0x2 0xB0 0x1800000 0x2 0x24 0x8000 0x2 0x24 0x4000 0x2 0x24 0x8000000>;
                syscon-names = "enable", "power_small", "power_large", "power_iso";
                sprd,ulps-disabled;
                phandle = <0xEC>;
                port@0 {
                    reg = <0x0>;
                    endpoint {
                        remote-endpoint = <0x45>;
                        phandle = <0x44>;
                    };
                };
                port@1 {
                    reg = <0x1>;
                    endpoint {
                        remote-endpoint = <0x46>;
                        phandle = <0x42>;
                    };
                };
            };
            mipi-csi-phy0 {
                compatible = "sprd,mipi-csi-phy";
                sprd,phyid = <0x0>;
                sprd,phyname = "2p2";
                status = "disabled";
                phandle = <0xED>;
            };
            mipi-csi-phy1 {
                compatible = "sprd,mipi-csi-phy";
                sprd,phyid = <0x1>;
                sprd,phyname = "4lane";
                status = "disabled";
                phandle = <0xEE>;
            };
            mipi-csi-phy2 {
                compatible = "sprd,mipi-csi-phy";
                sprd,phyid = <0x2>;
                sprd,phyname = "2lane";
                status = "disabled";
                phandle = <0xEF>;
            };
            mipi-csi-phy0-s {
                compatible = "sprd,mipi-csi-phy";
                sprd,phyid = <0x3>;
                sprd,phyname = "2p2_m";
                status = "disabled";
                phandle = <0xF0>;
            };
            mipi-csi-phy0-m {
                compatible = "sprd,mipi-csi-phy";
                sprd,phyid = <0x4>;
                sprd,phyname = "2p2_s";
                status = "disabled";
                phandle = <0xF1>;
            };
            mipi-csi-phy0-m1 {
                compatible = "sprd,mipi-csi-phy";
                sprd,phyid = <0x4>;
                sprd,phyname = "2p2_s";
                status = "disabled";
                phandle = <0xF2>;
            };
            dcam@60a00000 {
                compatible = "sprd,sharkl3-cam";
                reg = <0x60A00000 0x1000 0x60A01000 0x1000 0x60A02000 0x1000 0x60A03000 0x1000>;
                reg_name = "dcam0_reg", "dcam1_reg", "dcam2_reg", "axi_ctrl_reg";
                interrupts = <0x0 0x2D 0x4 0x0 0x9E 0x4 0x0 0x9F 0x4>;
                interrupts_name = "dcam0", "dcam1", "dcam2";
                syscons = <0x47 0x4 0x40 0x47 0x4 0x4 0x47 0x4 0x8 0x47 0x4 0x10>;
                syscon-names = "dcam_all_reset", "dcam0_reset", "dcam1_reset", "dcam2_reset";
                sprd,aon-apb-syscon = <0x2>;
                sprd,cam-ahb-syscon = <0x47>;
                sprd,isp = <0x48>;
                sprd,dcam-count = <0x3>;
                sprd,project-id = <0x0>;
                iommus = <0x49>;
                status = "okay";
                clock-names = "dcam_eb", "dcam_axi_eb", "clk_cphy_cfg_gate_eb", "clk_mm_eb", "clk_mm_ahb", "clk_mm_ahb_parent", "clk_mm_emc", "clk_mm_emc_parent", "dcam_clk", "dcam_clk_256m", "dcam_clk_307m2", "dcam_clk_384m", "dcam_clk_parent", "dcam_bpc_clk", "dcam_bpc_clk_parent";
                clocks = <0x4A 0x1 0x4A 0x6 0x5 0x66 0x5 0x19 0x12 0x2A 0x6 0xF 0x12 0x29 0x6 0x8 0x12 0x2C 0x6 0x9 0x6 0xC 0x6 0x2 0x6 0x2 0x12 0x2B 0x4B 0x3>;
                phandle = <0xF3>;
            };
            iommu@60a0c000 {
                compatible = "sprd,iommuex-dcam";
                reg = <0x60A0C000 0x60>;
                sprd,frc-reg = <0x60A03010>;
                sprd,iova-base = <0x40000000>;
                sprd,iova-size = <0x20000000>;
                reg_name = "mmu_reg";
                status = "okay";
                #iommu-cells = <0x0>;
                phandle = <0x49>;
            };
            isp@60b00000 {
                compatible = "sprd,isp";
                reg = <0x60B00000 0x100000>;
                interrupts = <0x0 0x2C 0x4 0x0 0x7D 0x4>;
                interrupts_name = "ch0", "ch1";
                syscons = <0x47 0x4 0x80>;
                syscon-names = "reset";
                sprd,cam-ahb-syscon = <0x47>;
                sprd,isp-count = <0x1>;
                iommus = <0x4C>;
                status = "okay";
                clock-names = "isp_eb", "isp_axi_eb", "isp_clk", "isp_clk_128m", "isp_clk_256m", "isp_clk_307m2", "isp_clk_384m", "isp_clk_468m", "isp_clk_parent";
                clocks = <0x4A 0x2 0x4A 0x7 0x12 0x2D 0x6 0xA 0x6 0x9 0x6 0xC 0x6 0x2 0x6 0x19 0x6 0x19>;
                phandle = <0x48>;
            };
            iommu@60bffc00 {
                compatible = "sprd,iommuex-isp";
                reg = <0x60BFFC00 0x400>;
                sprd,iova-base = <0x50000000>;
                sprd,iova-size = <0x20000000>;
                reg_name = "mmu_reg";
                status = "okay";
                #iommu-cells = <0x0>;
                phandle = <0x4C>;
            };
            csi@60c00000 {
                compatible = "sprd,csi-controller";
                reg = <0x60C00000 0x1000>;
                interrupts = <0x0 0x28 0x4 0x0 0x29 0x4>;
                sprd,aon-apb-syscon = <0x2>;
                sprd,cam-ahb-syscon = <0x47>;
                sprd,anlg_phy_g1_controller = <0x3>;
                sprd,csi-id = <0x0>;
                sprd,dcam-id = <0x0>;
                sprd,ip-version = <0x200>;
                status = "okay";
                clock-names = "clk_mipi_csi_gate_eb", "clk_csi_eb", "mipi_csi_src_eb", "clk_gate_eb";
                clocks = <0x4A 0x8 0x4A 0x3 0x4D 0x0 0x4A 0x0>;
                phandle = <0xF4>;
            };
            csi@60d00000 {
                compatible = "sprd,csi-controller";
                reg = <0x60D00000 0x1000>;
                interrupts = <0x0 0x47 0x4 0x0 0x48 0x4>;
                sprd,aon-apb-syscon = <0x2>;
                sprd,cam-ahb-syscon = <0x47>;
                sprd,anlg_phy_g1_controller = <0x3>;
                sprd,csi-id = <0x1>;
                sprd,dcam-id = <0x1>;
                sprd,ip-version = <0x200>;
                status = "okay";
                clock-names = "clk_mipi_csi_gate_eb", "clk_csi_eb", "mipi_csi_src_eb", "clk_gate_eb";
                clocks = <0x4A 0x9 0x4A 0x4 0x4D 0x1 0x4A 0x0>;
                phandle = <0xF5>;
            };
            csi@60e00000 {
                compatible = "sprd,csi-controller";
                reg = <0x60E00000 0x1000>;
                interrupts = <0x0 0x9C 0x4 0x0 0x9D 0x4>;
                sprd,aon-apb-syscon = <0x2>;
                sprd,cam-ahb-syscon = <0x47>;
                sprd,anlg_phy_g1_controller = <0x3>;
                sprd,csi-id = <0x2>;
                sprd,dcam-id = <0x2>;
                sprd,ip-version = <0x200>;
                status = "okay";
                clock-names = "clk_mipi_csi_gate_eb", "clk_csi_eb", "mipi_csi_src_eb", "clk_gate_eb";
                clocks = <0x4A 0xA 0x4A 0x5 0x4D 0x2 0x4A 0x0>;
                phandle = <0xF6>;
            };
            cpp@62400000 {
                compatible = "sprd,cpp";
                reg = <0x62400000 0x1000>;
                interrupts = <0x0 0x7E 0x4>;
                syscons = <0x3E 0x4 0x3C0 0x3E 0x4 0x80 0x3E 0x4 0x100 0x3E 0x4 0x200>;
                syscon-names = "cpp_rst", "path0_rst", "path1_rst", "dma_rst";
                iommus = <0x4E>;
                status = "okay";
                clock-names = "cpp_eb", "cpp_clk", "cpp_clk_parent", "clk_mm_vsp_eb", "clk_mm_vsp_emc", "clk_mm_vsp_emc_parent";
                clocks = <0x40 0x3 0x12 0x2F 0x6 0xC 0x5 0x2C 0x12 0x33 0x6 0x19>;
                phandle = <0xF7>;
            };
            iommu@62400200 {
                compatible = "sprd,iommuex-cpp";
                reg = <0x62400200 0x60>;
                sprd,iova-base = <0x60000000>;
                sprd,iova-size = <0x8000000>;
                reg_name = "mmu_reg", "iova pool";
                status = "okay";
                #iommu-cells = <0x0>;
                phandle = <0x4E>;
            };
        };
        pub {
            compatible = "simple-bus";
            #address-cells = <0x1>;
            #size-cells = <0x1>;
            ranges;
            dmc-controller@30000000 {
                compatible = "sprd,sharkl3-dmc";
                reg = <0x30000000 0x1000>;
                phandle = <0xF8>;
            };
            ptm@30010000 {
                compatible = "sprd,sharkl3-ptm";
                reg = <0x30010000 0x10000 0x10001000 0x1000 0x10003000 0x1000 0x10004000 0x1000>;
                interrupts = <0x0 0x56 0x4>;
                clock-names = "clk_cs", "cs_src";
                clocks = <0x12 0x18 0x6 0xF>;
                sprd,funnel-port = <0x2>;
                sprd,ddr-chn = <0x8>;
                sprd,chn-name = "MM", "GPU", "DPU", "CPU", "AP/PUBCP", "WTLCP", "WCN/AON/ETR", "VSP";
                phandle = <0xF9>;
            };
            dmc-mpu@300e0000 {
                compatible = "sprd,sharkl3-dmc-mpu";
                reg = <0x300E0000 0x10000>;
                interrupts = <0x0 0x3D 0x4>;
                syscon-names = "irq_clr", "irq_en";
                syscons = <0x4F 0x40 0x2 0x4F 0x40 0x1>;
                sprd,channel-num = <0x8>;
                sprd,mpu-num = <0x10>;
                sprd,channel-names = "MM", "GPU", "DPU", "CPU", "AP/PUBCP", "WTLCP", "AON/WCN/ETR", "VSP", "SHARED0", "SHARED1", "SHARED2", "SHARED3", "SHARED4", "SHARED5", "SHARED6", "SHARED7";
                sprd,ranges = <0x0 0x0 0x0 0x0 0x0 0x0 0x0 0x0 0x0 0x0 0x0 0x0 0x0 0x0 0x0 0x0 0x0 0x0 0x0 0x0 0x0 0x0 0x0 0x0 0x0 0x0 0x0 0x0 0x0 0x0 0x0 0x0 0x0 0x0 0x0 0x0 0x0 0x0 0x0 0x0 0x0 0x0 0x0 0x0 0x0 0x0 0x0 0x0 0x0 0x0 0x0 0x0 0x0 0x0 0x0 0x0 0x0 0x0 0x0 0x0 0x0 0x0 0x0 0x0>;
                sprd,chn-config = <0x0 0x1 0x1 0x0 0x1 0x1 0x0 0x1 0x1 0x0 0x1 0x1 0x0 0x1 0x1 0x0 0x1 0x1 0x0 0x1 0x1 0x0 0x1 0x1 0x0 0x1 0x1 0x0 0x1 0x1 0x0 0x1 0x1 0x0 0x1 0x1 0x0 0x1 0x1 0x0 0x1 0x1 0x0 0x1 0x1 0x0 0x1 0x1>;
                sprd,id-config = <0x0 0x0 0xFFFF 0x0 0x0 0xFFFF 0x0 0x0 0xFFFF 0x0 0x0 0xFFFF 0x0 0x0 0xFFFF 0x0 0x0 0xFFFF 0x0 0x0 0xFFFF 0x0 0x0 0xFFFF 0x0 0x0 0xFFFF 0x0 0x0 0xFFFF 0x0 0x0 0xFFFF 0x0 0x0 0xFFFF 0x0 0x0 0xFFFF 0x0 0x0 0xFFFF 0x0 0x0 0xFFFF 0x0 0x0 0xFFFF>;
                sprd,port-map = <0x0 0x1 0x2 0x3 0x4 0x5 0x6 0x7 0x0 0x0 0x0 0x0 0x0 0x0 0x0 0x0>;
                sprd,ddr-offset = <0x80000000>;
                status = "disabled";
                phandle = <0xFA>;
            };
        };
        pmu-gate {
            compatible = "sprd,sc9863a-pmu-gate";
            sprd,syscon = <0x7>;
            clocks = <0xA>;
            #clock-cells = <0x1>;
            phandle = <0x50>;
        };
        pll {
            compatible = "sprd,sc9863a-pll";
            sprd,syscon = <0x4>;
            clocks = <0x50 0x0>;
            #clock-cells = <0x1>;
            phandle = <0x6>;
        };
        mpll {
            compatible = "sprd,sc9863a-mpll";
            sprd,syscon = <0xF>;
            clocks = <0x50 0x0>;
            #clock-cells = <0x1>;
            phandle = <0x82>;
        };
        rpll {
            compatible = "sprd,sc9863a-rpll";
            sprd,syscon = <0x51>;
            clocks = <0x50 0x0>;
            #clock-cells = <0x1>;
            phandle = <0x13>;
        };
        dpll {
            compatible = "sprd,sc9863a-dpll";
            sprd,syscon = <0x17>;
            clocks = <0x50 0x0>;
            #clock-cells = <0x1>;
            phandle = <0x4B>;
        };
        clock-controller@21500000 {
            compatible = "sprd,sc9863a-ap-clk";
            reg = <0x21500000 0x1000>;
            clocks = <0x2C 0xA 0x6 0x0 0x13 0x0>;
            #clock-cells = <0x1>;
            phandle = <0x9>;
        };
        clock-controller@402d0000 {
            compatible = "sprd,sc9863a-aon-clk";
            reg = <0x402D0000 0x1000>;
            clocks = <0xA 0x6 0x0 0x13 0x0 0x4B 0x0>;
            #clock-cells = <0x1>;
            phandle = <0x12>;
        };
        apahb-gate {
            compatible = "sprd,sc9863a-apahb-gate";
            sprd,syscon = <0xE>;
            clocks = <0x12 0x1D>;
            #clock-cells = <0x1>;
            phandle = <0xC>;
        };
        aonapb-gate {
            compatible = "sprd,sc9863a-aonapb-gate";
            sprd,syscon = <0x2>;
            clocks = <0x12 0x9>;
            #clock-cells = <0x1>;
            phandle = <0x5>;
        };
        mm-gate {
            compatible = "sprd,sc9863a-mm-gate";
            sprd,syscon = <0x47>;
            clocks = <0x12 0x2A>;
            #clock-cells = <0x1>;
            phandle = <0x4A>;
        };
        clock-controller@60900000 {
            compatible = "sprd,sc9863a-mm-clk";
            reg = <0x60900000 0x1000>;
            clocks = <0x12 0x2A>;
            #clock-cells = <0x1>;
            phandle = <0x4D>;
        };
        vspahb-gate {
            compatible = "sprd,sc9863a-vspahb-gate";
            sprd,syscon = <0x3E>;
            clocks = <0x12 0x2A>;
            #clock-cells = <0x1>;
            phandle = <0x40>;
        };
        apapb-gate {
            compatible = "sprd,sc9863a-apapb-gate";
            sprd,syscon = <0xB>;
            clocks = <0xA>;
            #clock-cells = <0x1>;
            phandle = <0x8>;
        };
        funnel@10001000 {
            compatible = "arm,coresight-funnel", "arm,primecell";
            reg = <0x10001000 0x1000>;
            clocks = <0xA>;
            clock-names = "apb_pclk";
            ports {
                #address-cells = <0x1>;
                #size-cells = <0x0>;
                port@0 {
                    reg = <0x0>;
                    endpoint {
                        remote-endpoint = <0x52>;
                        phandle = <0x54>;
                    };
                };
                port@1 {
                    reg = <0x0>;
                    endpoint {
                        slave-mode;
                        remote-endpoint = <0x53>;
                        phandle = <0x5E>;
                    };
                };
            };
        };
        etb@10003000 {
            compatible = "arm,coresight-tmc", "arm,primecell";
            reg = <0x10003000 0x1000>;
            clocks = <0xA>;
            clock-names = "apb_pclk";
            port {
                endpoint {
                    slave-mode;
                    remote-endpoint = <0x54>;
                    phandle = <0x52>;
                };
            };
        };
        funnel@12001000 {
            compatible = "arm,coresight-funnel", "arm,primecell";
            reg = <0x12001000 0x1000>;
            clocks = <0xA>;
            clock-names = "apb_pclk";
            ports {
                #address-cells = <0x1>;
                #size-cells = <0x0>;
                port@0 {
                    reg = <0x0>;
                    endpoint {
                        remote-endpoint = <0x55>;
                        phandle = <0x5B>;
                    };
                };
                port@1 {
                    reg = <0x0>;
                    endpoint {
                        slave-mode;
                        remote-endpoint = <0x56>;
                        phandle = <0x67>;
                    };
                };
                port@2 {
                    reg = <0x1>;
                    endpoint {
                        slave-mode;
                        remote-endpoint = <0x57>;
                        phandle = <0x69>;
                    };
                };
                port@3 {
                    reg = <0x2>;
                    endpoint {
                        slave-mode;
                        remote-endpoint = <0x58>;
                        phandle = <0x6B>;
                    };
                };
                port@4 {
                    reg = <0x3>;
                    endpoint {
                        slave-mode;
                        remote-endpoint = <0x59>;
                        phandle = <0x6D>;
                    };
                };
            };
        };
        etf@12002000 {
            compatible = "arm,coresight-tmc", "arm,primecell";
            reg = <0x12002000 0x1000>;
            clocks = <0xA>;
            clock-names = "apb_pclk";
            port@0 {
                endpoint {
                    remote-endpoint = <0x5A>;
                    phandle = <0x5F>;
                };
            };
            port@1 {
                endpoint {
                    slave-mode;
                    remote-endpoint = <0x5B>;
                    phandle = <0x55>;
                };
            };
        };
        etf@12003000 {
            compatible = "arm,coresight-tmc", "arm,primecell";
            reg = <0x12003000 0x1000>;
            clocks = <0xA>;
            clock-names = "apb_pclk";
            port@0 {
                endpoint {
                    remote-endpoint = <0x5C>;
                    phandle = <0x60>;
                };
            };
            port@1 {
                endpoint {
                    slave-mode;
                    remote-endpoint = <0x5D>;
                    phandle = <0x61>;
                };
            };
        };
        funnel@12004000 {
            compatible = "arm,coresight-funnel", "arm,primecell";
            reg = <0x12004000 0x1000>;
            clocks = <0xA>;
            clock-names = "apb_pclk";
            ports {
                #address-cells = <0x1>;
                #size-cells = <0x0>;
                port@0 {
                    reg = <0x0>;
                    endpoint {
                        remote-endpoint = <0x5E>;
                        phandle = <0x53>;
                    };
                };
                port@1 {
                    reg = <0x0>;
                    endpoint {
                        slave-mode;
                        remote-endpoint = <0x5F>;
                        phandle = <0x5A>;
                    };
                };
                port@2 {
                    reg = <0x1>;
                    endpoint {
                        slave-mode;
                        remote-endpoint = <0x60>;
                        phandle = <0x5C>;
                    };
                };
            };
        };
        funnel@12005000 {
            compatible = "arm,coresight-funnel", "arm,primecell";
            reg = <0x12005000 0x1000>;
            clocks = <0xA>;
            clock-names = "apb_pclk";
            ports {
                #address-cells = <0x1>;
                #size-cells = <0x0>;
                port@0 {
                    reg = <0x0>;
                    endpoint {
                        remote-endpoint = <0x61>;
                        phandle = <0x5D>;
                    };
                };
                port@1 {
                    reg = <0x0>;
                    endpoint {
                        slave-mode;
                        remote-endpoint = <0x62>;
                        phandle = <0x6F>;
                    };
                };
                port@2 {
                    reg = <0x1>;
                    endpoint {
                        slave-mode;
                        remote-endpoint = <0x63>;
                        phandle = <0x71>;
                    };
                };
                port@3 {
                    reg = <0x2>;
                    endpoint {
                        slave-mode;
                        remote-endpoint = <0x64>;
                        phandle = <0x73>;
                    };
                };
                port@4 {
                    reg = <0x3>;
                    endpoint {
                        slave-mode;
                        remote-endpoint = <0x65>;
                        phandle = <0x75>;
                    };
                };
            };
        };
        etm@13040000 {
            compatible = "arm,coresight-etm4x", "arm,primecell";
            reg = <0x13040000 0x1000>;
            cpu = <0x66>;
            clocks = <0xA>;
            clock-names = "apb_pclk";
            port {
                endpoint {
                    remote-endpoint = <0x67>;
                    phandle = <0x56>;
                };
            };
        };
        etm@13140000 {
            compatible = "arm,coresight-etm4x", "arm,primecell";
            reg = <0x13140000 0x1000>;
            cpu = <0x68>;
            clocks = <0xA>;
            clock-names = "apb_pclk";
            port {
                endpoint {
                    remote-endpoint = <0x69>;
                    phandle = <0x57>;
                };
            };
        };
        etm@13240000 {
            compatible = "arm,coresight-etm4x", "arm,primecell";
            reg = <0x13240000 0x1000>;
            cpu = <0x6A>;
            clocks = <0xA>;
            clock-names = "apb_pclk";
            port {
                endpoint {
                    remote-endpoint = <0x6B>;
                    phandle = <0x58>;
                };
            };
        };
        etm@13340000 {
            compatible = "arm,coresight-etm4x", "arm,primecell";
            reg = <0x13340000 0x1000>;
            cpu = <0x6C>;
            clocks = <0xA>;
            clock-names = "apb_pclk";
            port {
                endpoint {
                    remote-endpoint = <0x6D>;
                    phandle = <0x59>;
                };
            };
        };
        etm@13440000 {
            compatible = "arm,coresight-etm4x", "arm,primecell";
            reg = <0x13440000 0x1000>;
            cpu = <0x6E>;
            clocks = <0xA>;
            clock-names = "apb_pclk";
            port {
                endpoint {
                    remote-endpoint = <0x6F>;
                    phandle = <0x62>;
                };
            };
        };
        etm@13540000 {
            compatible = "arm,coresight-etm4x", "arm,primecell";
            reg = <0x13540000 0x1000>;
            cpu = <0x70>;
            clocks = <0xA>;
            clock-names = "apb_pclk";
            port {
                endpoint {
                    remote-endpoint = <0x71>;
                    phandle = <0x63>;
                };
            };
        };
        etm@13640000 {
            compatible = "arm,coresight-etm4x", "arm,primecell";
            reg = <0x13640000 0x1000>;
            cpu = <0x72>;
            clocks = <0xA>;
            clock-names = "apb_pclk";
            port {
                endpoint {
                    remote-endpoint = <0x73>;
                    phandle = <0x64>;
                };
            };
        };
        etm@13740000 {
            compatible = "arm,coresight-etm4x", "arm,primecell";
            reg = <0x13740000 0x1000>;
            cpu = <0x74>;
            clocks = <0xA>;
            clock-names = "apb_pclk";
            port {
                endpoint {
                    remote-endpoint = <0x75>;
                    phandle = <0x65>;
                };
            };
        };
    };
    ext-26m {
        compatible = "fixed-clock";
        #clock-cells = <0x0>;
        clock-frequency = <0x18CBA80>;
        clock-output-names = "ext-26m";
        phandle = <0xA>;
    };
    ext-13m {
        compatible = "fixed-clock";
        #clock-cells = <0x0>;
        clock-frequency = <0xC65D40>;
        clock-output-names = "ext_13m";
        phandle = <0xFB>;
    };
    ext-6m5 {
        compatible = "fixed-clock";
        #clock-cells = <0x0>;
        clock-frequency = <0x632EA0>;
        clock-output-names = "ext_6m5";
        phandle = <0xFC>;
    };
    ext-4m3 {
        compatible = "fixed-clock";
        #clock-cells = <0x0>;
        clock-frequency = <0x419CE0>;
        clock-output-names = "ext_4m3";
        phandle = <0xFD>;
    };
    ext-4m {
        compatible = "fixed-clock";
        #clock-cells = <0x0>;
        clock-frequency = <0x3D0900>;
        clock-output-names = "ext_4m";
        phandle = <0xFE>;
    };
    ext-250k {
        compatible = "fixed-clock";
        #clock-cells = <0x0>;
        clock-frequency = <0x3D090>;
        clock-output-names = "ext_250k";
        phandle = <0xFF>;
    };
    ext-32k {
        compatible = "fixed-clock";
        #clock-cells = <0x0>;
        clock-frequency = <0x8000>;
        clock-output-names = "ext_32k";
        phandle = <0x2C>;
    };
    ext-1m {
        compatible = "fixed-clock";
        #clock-cells = <0x0>;
        clock-frequency = <0xF4240>;
        clock-output-names = "ext_1m";
        phandle = <0x100>;
    };
    ext-2m {
        compatible = "fixed-clock";
        #clock-cells = <0x0>;
        clock-frequency = <0x1E8480>;
        clock-output-names = "ext_2m";
        phandle = <0x101>;
    };
    ext-rc0-4m {
        compatible = "fixed-clock";
        #clock-cells = <0x0>;
        clock-frequency = <0x3D0900>;
        clock-output-names = "ext_rc0_4m";
        phandle = <0x102>;
    };
    clk-pad {
        compatible = "fixed-clock";
        #clock-cells = <0x0>;
        clock-frequency = <0x3D09000>;
        clock-output-names = "clk_pad";
        phandle = <0x103>;
    };
    rco-100m {
        compatible = "fixed-clock";
        #clock-cells = <0x0>;
        clock-frequency = <0x5F5E100>;
        clock-output-names = "rco-100m";
        phandle = <0x104>;
    };
    sprd-pcm-audio {
        compatible = "sprd,sharkl3-pcm-platform";
        #sound-dai-cells = <0x0>;
        dmas = <0x76 0x1 0x76 0x2 0x76 0x3 0x76 0x4 0x76 0x5 0x76 0x6 0x76 0x7 0x76 0x8 0x76 0x5 0x76 0x6>;
        dma-names = "da01-l", "da01-r", "da23-l", "da23-r", "normal-2stage-p", "normal-2stage-c", "deep-2stage-p", "ad23-2stage-c", "ad01-l", "ad01-r";
        sprd,dma-2stage-usecase = <0x2>;
        sprd,node-count-2stage-level-1 = <0x1>;
        sprd,syscon-pmu-apb = <0x7>;
        sprd,dma-2stage-level-1-int-source = <0x1>;
        phandle = <0x9D>;
    };
    vaudio {
        compatible = "sprd,vaudio";
        #sound-dai-cells = <0x1>;
        clock-names = "tuned_26m";
        clocks = <0x13 0x0>;
        phandle = <0xA0>;
    };
    sprd-pcm-iis {
        compatible = "sprd,sharkl3-pcm-platform";
        #sound-dai-cells = <0x0>;
        dmas = <0x77 0x5 0x77 0x6>;
        dma-names = "iis0_tx", "iis0_rx";
        sprd,dma-2stage-usecase = <0x2>;
        sprd,node-count-2stage-level-1 = <0x1>;
        sprd,syscon-pmu-apb = <0x7>;
        sprd,dma-2stage-level-1-int-source = <0x1>;
        phandle = <0xA1>;
    };
    saudio_lte {
        compatible = "sprd,saudio";
        sprd,saudio-dst-id = <0x5>;
        sprd,ctrl_channel = <0xA>;
        sprd,playback_channel = <0xB 0x83 0x84>;
        sprd,capture_channel = <0xC>;
        sprd,monitor_channel = <0xD>;
        sprd,device = <0x3>;
        sprd,saudio-names = "saudiolte";
    };
    saudio_voip {
        compatible = "sprd,saudio";
        sprd,saudio-dst-id = <0x5>;
        sprd,ctrl_channel = <0xE>;
        sprd,playback_channel = <0xF 0x97>;
        sprd,capture_channel = <0x10>;
        sprd,monitor_channel = <0x11>;
        sprd,device = <0x2>;
        sprd,saudio-names = "saudiovoip";
    };
    audio-mem-mgr {
        compatible = "sprd,sharkl3-audio-mem";
        sprd,iram_phy_addr = <0x2000 0xB000>;
        sprd,iram_normal = <0x2000 0x0>;
        sprd,iram_deepbuf = <0x2000 0xA000>;
        sprd,iram_4arm7 = <0xC000 0x1000>;
    };
    apipe-pcm {
        compatible = "sprd,apipe";
    };
    apipe-cmd-in {
        compatible = "sprd,apipe";
    };
    apipe-cmd-out {
        compatible = "sprd,apipe";
    };
    cpus {
        #address-cells = <0x1>;
        #size-cells = <0x0>;
        cpu-map {
            cluster0 {
                core0 {
                    cpu = <0x66>;
                };
                core1 {
                    cpu = <0x68>;
                };
                core2 {
                    cpu = <0x6A>;
                };
                core3 {
                    cpu = <0x6C>;
                };
            };
            cluster1 {
                core0 {
                    cpu = <0x6E>;
                };
                core1 {
                    cpu = <0x70>;
                };
                core2 {
                    cpu = <0x72>;
                };
                core3 {
                    cpu = <0x74>;
                };
            };
        };
        cpu@0 {
            device_type = "cpu";
            compatible = "arm,cortex-a55", "arm,armv8";
            reg = <0x0>;
            enable-method = "psci";
            cpu-supply = <0x78>;
            cpufreq-data-v1 = <0x79>;
            cpu-idle-states = <0x7A>;
            sched-energy-costs = <0x7B 0x7C>;
            capacity-dmips-mhz = <0x400>;
            sugov_slack_timer;
            phandle = <0x66>;
        };
        cpu@100 {
            device_type = "cpu";
            compatible = "arm,cortex-a55", "arm,armv8";
            reg = <0x100>;
            enable-method = "psci";
            cpu-supply = <0x78>;
            cpufreq-data-v1 = <0x79>;
            cpu-idle-states = <0x7A>;
            sched-energy-costs = <0x7B 0x7C>;
            capacity-dmips-mhz = <0x400>;
            phandle = <0x68>;
        };
        cpu@200 {
            device_type = "cpu";
            compatible = "arm,cortex-a55", "arm,armv8";
            reg = <0x200>;
            enable-method = "psci";
            cpu-supply = <0x78>;
            cpufreq-data-v1 = <0x79>;
            cpu-idle-states = <0x7A>;
            sched-energy-costs = <0x7B 0x7C>;
            capacity-dmips-mhz = <0x400>;
            phandle = <0x6A>;
        };
        cpu@300 {
            device_type = "cpu";
            compatible = "arm,cortex-a55", "arm,armv8";
            reg = <0x300>;
            enable-method = "psci";
            cpu-supply = <0x78>;
            cpufreq-data-v1 = <0x79>;
            cpu-idle-states = <0x7A>;
            sched-energy-costs = <0x7B 0x7C>;
            capacity-dmips-mhz = <0x400>;
            phandle = <0x6C>;
        };
        cpu@400 {
            device_type = "cpu";
            compatible = "arm,cortex-a55", "arm,armv8";
            reg = <0x400>;
            enable-method = "psci";
            cpu-supply = <0x7D>;
            cpufreq-data-v1 = <0x7E>;
            cpu-idle-states = <0x7A>;
            sched-energy-costs = <0x7F 0x80>;
            capacity-dmips-mhz = <0x400>;
            phandle = <0x6E>;
        };
        cpu@500 {
            device_type = "cpu";
            compatible = "arm,cortex-a55", "arm,armv8";
            reg = <0x500>;
            enable-method = "psci";
            cpu-supply = <0x7D>;
            cpufreq-data-v1 = <0x7E>;
            cpu-idle-states = <0x7A>;
            sched-energy-costs = <0x7F 0x80>;
            capacity-dmips-mhz = <0x400>;
            phandle = <0x70>;
        };
        cpu@600 {
            device_type = "cpu";
            compatible = "arm,cortex-a55", "arm,armv8";
            reg = <0x600>;
            enable-method = "psci";
            cpu-supply = <0x7D>;
            cpufreq-data-v1 = <0x7E>;
            cpu-idle-states = <0x7A>;
            sched-energy-costs = <0x7F 0x80>;
            capacity-dmips-mhz = <0x400>;
            phandle = <0x72>;
        };
        cpu@700 {
            device_type = "cpu";
            compatible = "arm,cortex-a55", "arm,armv8";
            reg = <0x700>;
            enable-method = "psci";
            cpu-supply = <0x7D>;
            cpufreq-data-v1 = <0x7E>;
            cpu-idle-states = <0x7A>;
            sched-energy-costs = <0x7F 0x80>;
            capacity-dmips-mhz = <0x400>;
            phandle = <0x74>;
        };
    };
    energy-costs {
        core-cost0 {
            busy-cost-data = <0x1EC 0x50 0x236 0x65 0x280 0x7D 0x2C0 0x97 0x300 0xB5>;
            idle-cost-data = <0x19 0x19 0x0>;
            phandle = <0x7B>;
        };
        core-cost1 {
            busy-cost-data = <0x1EC 0x6E 0x2A0 0xA0 0x310 0xCE 0x380 0x102 0x3C0 0x131 0x400 0x160>;
            idle-cost-data = <0x2C 0x2C 0x0>;
            phandle = <0x7F>;
        };
        cluster-cost0 {
            busy-cost-data = <0x1EC 0x1 0x236 0x2 0x280 0x3 0x2C0 0x4 0x300 0x5>;
            idle-cost-data = <0x0 0x0 0x0>;
            phandle = <0x7C>;
        };
        cluster-cost1 {
            busy-cost-data = <0x1EC 0x44 0x2A0 0x55 0x310 0x6A 0x380 0x82 0x3C0 0x99 0x400 0xB3>;
            idle-cost-data = <0x2A 0x2A 0x2A>;
            phandle = <0x80>;
        };
    };
    idle-states {
        entry-method = "arm,psci";
        core_pd {
            compatible = "arm,idle-state";
            entry-latency-us = <0x3E8>;
            exit-latency-us = <0x1F4>;
            min-residency-us = <0x9C4>;
            local-timer-stop;
            arm,psci-suspend-param = <0x10000>;
            phandle = <0x7A>;
        };
    };
    cpufreq-clus0 {
        cpufreq-cluster-id = <0x0>;
        nvmem-cells = <0x81>;
        nvmem-cell-names = "dvfs_bin";
        sprd,cpufreq-temp-threshold = <0x41>;
        clocks = <0x12 0x36 0x12 0x37 0x12 0x38 0x12 0x39 0x6 0x1 0x82 0x0>;
        clock-names = "core_clk", "core1_clk", "core2_clk", "core3_clk", "low_freq_clk_parent", "high_freq_clk_parent";
        clock-latency = <0xC350>;
        voltage-tolerance = <0x190D>;
        volt-share-masters-bits = <0x1>;
        operating-points = <0x124F80 0x111E53 0x10C8E0 0x106738 0xF4240 0xFB01D 0xD7D20 0xEE098 0xBB800 0xE04DE>;
        operating-points-1 = <0x124F80 0x100590 0x10C8E0 0xF5AAA 0xF4240 0xEA38F 0xD7D20 0xDC7D5 0xBB800 0xDBBA0>;
        operating-points-2 = <0x124F80 0x10C8E0 0x10C8E0 0x101DFA 0xF4240 0xF66DF 0xD7D20 0xE8B25 0xBB800 0xDBBA0>;
        operating-points-3 = <0x124F80 0x118C30 0x10C8E0 0x10E14A 0xF4240 0x102A2F 0xD7D20 0xF4E75 0xBB800 0xE7EF0>;
        operating-points-1-65 = <0x124F80 0x105B03 0x10C8E0 0xFA3E8 0xF4240 0xEECCD 0xD7D20 0xE1D48 0xBB800 0xDBBA0>;
        operating-points-2-65 = <0x124F80 0x111E53 0x10C8E0 0x106738 0xF4240 0xFB01D 0xD7D20 0xEE098 0xBB800 0xE04DE>;
        operating-points-3-65 = <0x10C8E0 0x112A88 0xF4240 0x10736D 0xD7D20 0xFA3E8 0xBB800 0xEC82E>;
        phandle = <0x79>;
    };
    cpufreq-clus1 {
        cpufreq-cluster-id = <0x1>;
        nvmem-cells = <0x83>;
        nvmem-cell-names = "dvfs_bin";
        sprd,cpufreq-temp-threshold = <0x41>;
        cpufreq-sub-clusters = <0x84>;
        clocks = <0x12 0x3A 0x12 0x3B 0x12 0x3C 0x12 0x3D 0x6 0x1 0x82 0x1>;
        clock-names = "core_clk", "core1_clk", "core2_clk", "core3_clk", "low_freq_clk_parent", "high_freq_clk_parent";
        clock-latency = <0xC350>;
        voltage-tolerance = <0x0>;
        volt-share-masters-bits = <0xA>;
        freq-sync-slaves-bits = <0x8>;
        operating-points = <0x186A00 0x111E53 0x16E360 0x108BD7 0x155CC0 0x100590 0x12B128 0xF0537 0x100590 0xE1113 0xBB800 0xDBBA0>;
        operating-points-1 = <0x186A00 0x100590 0x16E360 0xF7F49 0x155CC0 0xEECCD 0x12B128 0xDF8A9 0x100590 0xDBBA0 0xBB800 0xDBBA0>;
        operating-points-2 = <0x186A00 0x10C8E0 0x16E360 0x104299 0x155CC0 0xFB01D 0x12B128 0xEBBF9 0x100590 0xDC7D5 0xBB800 0xDBBA0>;
        operating-points-3 = <0x186A00 0x118C30 0x16E360 0x1105E9 0x155CC0 0x10736D 0x12B128 0xF7F49 0x100590 0xE8B25 0xBB800 0xDBBA0>;
        operating-points-1-65 = <0x186A00 0x105B03 0x16E360 0xFC887 0x155CC0 0xF4240 0x12B128 0xE41E7 0x100590 0xDBBA0 0xBB800 0xDBBA0>;
        operating-points-2-65 = <0x186A00 0x111E53 0x16E360 0x108BD7 0x155CC0 0x100590 0x12B128 0xF0537 0x100590 0xE1113 0xBB800 0xDBBA0>;
        operating-points-3-65 = <0x16E360 0x114F27 0x155CC0 0x10C8E0 0x12B128 0xFC887 0x100590 0xED463 0xBB800 0xDBBA0>;
        phandle = <0x7E>;
    };
    cpufreq-fcm {
        cpufreq-cluster-id = <0x3>;
        nvmem-cells = <0x85>;
        nvmem-cell-names = "dvfs_bin";
        sprd,cpufreq-temp-threshold = <0x41>;
        clocks = <0x12 0x3E 0x6 0x1 0x82 0x2>;
        clock-names = "clk", "clk_low", "clk_high";
        clock-latency = <0xC350>;
        voltage-tolerance = <0x0>;
        volt-share-masters-bits = <0xA>;
        freq-sync-hosts-bits = <0x2>;
        operating-points = <0x1312D0 0x111E53 0x11E220 0x108BD7 0x10B558 0x100590 0xEA218 0xF0537 0xC92C0 0xE1113 0xBB800 0xDBBA0>;
        operating-points-1 = <0x1312D0 0x100590 0x11E220 0xF7F49 0x10B558 0xEECCD 0xEA218 0xDF8A9 0xC92C0 0xDBBA0 0xBB800 0xDBBA0>;
        operating-points-2 = <0x1312D0 0x10C8E0 0x11E220 0x104299 0x10B558 0xFB01D 0xEA218 0xEBBF9 0xC92C0 0xDC7D5 0xBB800 0xDBBA0>;
        operating-points-3 = <0x1312D0 0x118C30 0x11E220 0x1105E9 0x10B558 0x10736D 0xEA218 0xF7F49 0xC92C0 0xE8B25 0xBB800 0xE1D48>;
        operating-points-1-65 = <0x1312D0 0x105B03 0x11E220 0xFC887 0x10B558 0xF4240 0xEA218 0xE41E7 0xC92C0 0xDBBA0 0xBB800 0xDBBA0>;
        operating-points-2-65 = <0x1312D0 0x111E53 0x11E220 0x108BD7 0x10B558 0x100590 0xEA218 0xF0537 0xC92C0 0xE1113 0xBB800 0xE04DE>;
        operating-points-3-65 = <0x11E220 0x114F27 0x10B558 0x10C8E0 0xEA218 0xFC887 0xC92C0 0xED463 0xBB800 0xEC82E>;
        phandle = <0x84>;
    };
    interrupt-controller@14000000 {
        compatible = "arm,gic-v3";
        #interrupt-cells = <0x3>;
        #address-cells = <0x1>;
        #size-cells = <0x1>;
        ranges;
        redistributor-stride = <0x20000>;
        #redistributor-regions = <0x1>;
        interrupt-controller;
        reg = <0x14000000 0x20000 0x14040000 0x100000>;
        interrupts = <0x1 0x9 0x4>;
        phandle = <0x1>;
        v2m@0 {
            compatible = "arm,gic-v2m-frame";
            msi-controller;
            reg = <0x0 0x1000>;
            phandle = <0x105>;
        };
    };
    psci {
        compatible = "arm,psci-0.2";
        method = "smc";
    };
    power-debug {
        compatible = "sprd,power-debug-sharkl3";
        sprd,enable = <0x1>;
        sprd,scan-interval = <0x1E>;
        sprd,sys-ap-ahb = <0xE>;
        sprd,sys-ap-apb = <0xB>;
        sprd,sys-pmu-apb = <0x7>;
        sprd,sys-aon-apb = <0x2>;
        sprd,sys-ap-intc = <0x86 0x87 0x88 0x89 0x8A 0x8B>;
        phandle = <0x106>;
    };
    timer {
        compatible = "arm,armv8-timer";
        interrupts = <0x1 0xD 0x4 0x1 0xE 0x4 0x1 0xB 0x4 0x1 0xA 0x4>;
        arm,no-tick-in-suspend;
    };
    pmu {
        compatible = "arm,armv8-pmuv3";
        interrupts = <0x0 0x90 0x4 0x0 0x91 0x4 0x0 0x92 0x4 0x0 0x93 0x4 0x0 0x94 0x4 0x0 0x95 0x4 0x0 0x96 0x4 0x0 0x97 0x4>;
    };
    sprd-gsp {
        compatible = "sprd,gsp-r6p0-sharkl3";
        core-cnt = <0x1>;
        io-cnt = <0x7>;
        cores = <0x8C>;
        power-domains = <0x3B>;
        phandle = <0xA9>;
    };
    cpwcn_btwf {
        compatible = "sprd,integrate_marlin";
        sprd,name = "wcn_btwf";
        sprd,syscon-ap-apb = <0x2>;
        sprd,syscon-ap-pmu = <0x7>;
        sprd,syscon-ap-pub-apb = <0x8D>;
        sprd,syscon-anlg-wrap-wcn = <0x8E>;
        sprd,syscon-wcn-reg = <0x8F>;
        sprd,syscon-anlg-phy-g5 = <0x51>;
        sprd,ctrl-probe-num = <0x2>;
        sprd,ctrl-reg = <0x2004 0x3198 0x2100 0x20CC 0x20B0 0x1008>;
        sprd,ctrl-mask = <0x3000000 0x7FF 0x3000000 0x80000 0x10400 0x80>;
        sprd,ctrl-value = <0x3000000 0x102 0x3000000 0x80000 0x10400 0x80>;
        sprd,ctrl-rw-offset = <0x2000 0x0 0x2000 0x2000 0x2000 0x1000>;
        sprd,ctrl-us-delay = <0xA 0xA 0xA 0xA 0xA 0xA>;
        sprd,ctrl-type = <0x3 0x0 0x1 0x1 0x1 0x3>;
        sprd,ctrl-shutdown-reg = <0x2008 0x10B0>;
        sprd,ctrl-shutdown-mask = <0x80 0x400>;
        sprd,ctrl-shutdown-value = <0x80 0x400>;
        sprd,ctrl-shutdown-rw-offset = <0x2000 0x1000>;
        sprd,ctrl-shutdown-us-delay = <0xA 0xA>;
        sprd,ctrl-shutdown-type = <0x3 0x1>;
        reg = <0x84000000 0x180000>;
        sprd,file-name = "/dev/block/platform/soc/soc:ap-ahb/20600000.sdio/by-name/wcnmodem";
        sprd,file-length = <0x178000>;
        memory_region = <0x90>;
        vddwcn-supply = <0x91>;
        vddwifipa-supply = <0x92>;
        #address-cells = <0x1>;
        #size-cells = <0x1>;
        nvmem-cells = <0x93 0x94 0x95 0x96>;
        nvmem-cell-names = "wcn_efuse_blk0", "wcn_efuse_blk1", "wcn_efuse_blk2", "wcn_efuse_blk3";
        phandle = <0x107>;
    };
    cpwcn_gnss {
        compatible = "sprd,integrate_gnss";
        sprd,name = "wcn_gnss";
        sprd,syscon-ap-apb = <0x2>;
        sprd,syscon-ap-pmu = <0x7>;
        sprd,syscon-ap-pub-apb = <0x8D>;
        sprd,syscon-anlg-wrap-wcn = <0x8E>;
        sprd,syscon-wcn-reg = <0x8F>;
        sprd,syscon-anlg-phy-g5 = <0x51>;
        sprd,ctrl-probe-num = <0x2>;
        sprd,ctrl-reg = <0x1004 0x3198 0x2100 0x20CC 0x20B0 0x1008>;
        sprd,ctrl-mask = <0xFFFFFF 0x7FF 0x3000000 0x80000 0x10800 0x40>;
        sprd,ctrl-value = <0x300000 0x102 0x3000000 0x80000 0x10800 0x40>;
        sprd,ctrl-rw-offset = <0x1000 0x0 0x2000 0x2000 0x2000 0x1000>;
        sprd,ctrl-us-delay = <0xA 0xA 0xA 0xA 0xA 0xA>;
        sprd,ctrl-type = <0x3 0x0 0x1 0x1 0x1 0x3>;
        sprd,ctrl-shutdown-reg = <0x2008 0x10B0>;
        sprd,ctrl-shutdown-mask = <0x40 0x800>;
        sprd,ctrl-shutdown-value = <0x40 0x800>;
        sprd,ctrl-shutdown-rw-offset = <0x2000 0x1000>;
        sprd,ctrl-shutdown-us-delay = <0xA 0xA>;
        sprd,ctrl-shutdown-type = <0x3 0x1>;
        reg = <0x84300000 0x100000>;
        sprd,file-name = "/dev/block/platform/soc/soc:ap-ahb/20600000.sdio/by-name/gpsgl";
        sprd,file-name-ext = "/dev/block/platform/soc/soc:ap-ahb/20600000.sdio/by-name/gpsbd";
        sprd,file-length = <0x100000>;
        memory_region = <0x97>;
        vddwcn-supply = <0x91>;
        #address-cells = <0x1>;
        #size-cells = <0x1>;
        nvmem-cells = <0x96 0x94 0x95>;
        nvmem-cell-names = "gnss_efuse_blk0", "gnss_efuse_blk1", "gnss_efuse_blk2";
        phandle = <0x108>;
    };
    wcn_sipc {
        compatible = "sprd,sipc";
        sipc@84180000 {
            sprd,name = "sipc-wcn";
            sprd,dst = <0x3 0x5>;
            sprd,smem-info = <0x84180000 0x180000 0x180000>;
            phandle = <0x109>;
        };
        sipc@8441b000 {
            sprd,name = "sipc-gnss";
            sprd,dst = <0x4 0x6>;
            sprd,smem-info = <0x8441B000 0x11B000 0x32000>;
            phandle = <0x10A>;
        };
    };
    wcn_spipe {
        compatible = "sprd,spipe";
        spipe_cpwcn {
            sprd,name = "spipe_wcn";
            sprd,dst = <0x3>;
            sprd,channel = <0x4>;
            sprd,ringnr = <0x10>;
            sprd,size-rxbuf = <0x2400>;
            sprd,size-txbuf = <0x2400>;
        };
        spipe_gnss {
            sprd,name = "sttygnss0";
            sprd,dst = <0x4>;
            sprd,channel = <0x4>;
            sprd,ringnr = <0x1>;
            sprd,size-rxbuf = <0x19000>;
            sprd,size-txbuf = <0xC800>;
        };
    };
    wcn_wifi_cmd {
        compatible = "sprd,swcnblk";
        sprd,name = "wcn_wifi_cmd";
        sprd,dst = <0x3>;
        sprd,channel = <0x7>;
        sprd,tx-blksize = <0x800>;
        sprd,tx-blknum = <0x4>;
        sprd,rx-blksize = <0x800>;
        sprd,rx-blknum = <0x10>;
    };
    wcn_wifi_data0 {
        compatible = "sprd,swcnblk";
        sprd,name = "wcn_wifi_data0";
        sprd,dst = <0x3>;
        sprd,channel = <0x8>;
        sprd,tx-blksize = <0x680>;
        sprd,tx-blknum = <0x40>;
        sprd,rx-blksize = <0x680>;
        sprd,rx-blknum = <0x100>;
    };
    wcn_wifi_data1 {
        compatible = "sprd,swcnblk";
        sprd,name = "wcn_wifi_data1";
        sprd,dst = <0x3>;
        sprd,channel = <0x9>;
        sprd,tx-blksize = <0x680>;
        sprd,tx-blknum = <0x40>;
        sprd,rx-blksize = <0x0>;
        sprd,rx-blknum = <0x0>;
    };
    wcn_bt {
        compatible = "sprd,wcn_internal_chip";
        sprd,name = "ttyBT";
        sprd,dst = <0x3>;
        sprd,channel = <0x4>;
        sprd,tx_bufid = <0xB>;
        sprd,rx_bufid = <0xA>;
    };
    wcn_fm {
        compatible = "sprd,wcn_internal_chip";
        sprd,name = "fm";
        sprd,dst = <0x3>;
        sprd,tx_channel = <0x4>;
        sprd,rx_channel = <0x4>;
        sprd,tx_bufid = <0xE>;
        sprd,rx_bufid = <0xD>;
    };
    gnss_common_ctl {
        compatible = "sprd,gnss_common_ctl";
        sprd,name = "gnss_common_ctl";
    };
    scproc-pubcp {
        compatible = "sprd,scproc_pubcp";
        #address-cells = <0x1>;
        #size-cells = <0x1>;
        ranges;
        scproc@800000 {
            sprd,name = "pmic";
            syscons = <0x2 0xFF 0x0 0x7 0xFF 0x100000 0x7 0xB0 0x80 0x2 0xFF 0x0 0x2 0xFF 0x0>;
            syscon-names = "shutdown", "deepsleep", "corereset", "sysreset", "getstatus";
            reg = <0x800000 0x40000>;
            #address-cells = <0x1>;
            #size-cells = <0x1>;
            ranges = <0x0 0x800000 0x3B000 0x3B000 0x83B000 0x5000>;
            phandle = <0x10B>;
            pm-sys@0 {
                cproc,name = "pm_sys";
                reg = <0x0 0x3B000>;
            };
            cali_lib@3b000 {
                cproc,name = "cali_lib";
                reg = <0x3B000 0x5000>;
            };
        };
        scproc@f000 {
            sprd,decoup = "cproc-use-decoup";
            sprd,name = "cptl";
            syscons = <0x7 0x48 0x2000000 0x7 0xCC 0x40000 0x2 0x284 0x400 0x7 0xB0 0x2 0x2 0xFF 0x0 0x2 0x130 0x30000>;
            syscon-names = "shutdown", "deepsleep", "corereset", "sysreset", "getstatus", "dspreset";
            reg = <0xF000 0x1000>;
            interrupts = <0x0 0x53 0x0>;
            phandle = <0x10C>;
        };
    };
    sprd-sipc {
        compatible = "sprd,sipc";
        sipc@88e00000 {
            sprd,name = "sipc-lte";
            sprd,dst = <0x5 0x2>;
            sprd,smem-info = <0x88E00000 0x88E00000 0x800000>;
            phandle = <0x10D>;
        };
        sipc@d000 {
            sprd,name = "sipc-pmsys";
            sprd,dst = <0x6 0x1 0x7>;
            sprd,smem-info = <0xD000 0x2000B000 0x2000>;
            phandle = <0x10E>;
        };
    };
    sprd-spipe {
        compatible = "sprd,spipe";
        spipe@0 {
            sprd,name = "spipe_pm";
            sprd,dst = <0x6>;
            sprd,channel = <0x4>;
            sprd,ringnr = <0x2>;
            sprd,size-rxbuf = <0xB00>;
            sprd,size-txbuf = <0x180>;
        };
        spipe@1 {
            sprd,name = "slog_pm";
            sprd,dst = <0x6>;
            sprd,channel = <0x5>;
            sprd,ringnr = <0x1>;
            sprd,size-rxbuf = <0x5C0>;
            sprd,size-txbuf = <0x20>;
        };
        spipe@2 {
            sprd,name = "sctl_pm";
            sprd,dst = <0x6>;
            sprd,channel = <0x6>;
            sprd,ringnr = <0x1>;
            sprd,size-rxbuf = <0x40>;
            sprd,size-txbuf = <0x20>;
        };
        spipe@3 {
            sprd,name = "spipe_lte";
            sprd,dst = <0x5>;
            sprd,channel = <0x4>;
            sprd,ringnr = <0xF>;
            sprd,size-rxbuf = <0x1000>;
            sprd,size-txbuf = <0x1000>;
        };
        spipe@4 {
            sprd,name = "sdiag_lte";
            sprd,dst = <0x5>;
            sprd,channel = <0x15>;
            sprd,ringnr = <0x1>;
            sprd,size-rxbuf = <0x20000>;
            sprd,size-txbuf = <0x8000>;
        };
        spipe@5 {
            sprd,name = "stty_lte";
            sprd,dst = <0x5>;
            sprd,channel = <0x6>;
            sprd,ringnr = <0x20>;
            sprd,size-rxbuf = <0x800>;
            sprd,size-txbuf = <0x800>;
        };
    };
    sprd-spool {
        compatible = "sprd,spool";
        sprd,name = "slog_lte";
        sprd,dst = <0x5>;
        sprd,channel = <0x5>;
        sprd,tx-blksize = <0x0>;
        sprd,tx-blknum = <0x0>;
        sprd,rx-blksize = <0x10000>;
        sprd,rx-blknum = <0x4>;
    };
    sprd-sipx {
        compatible = "sprd,sipx";
        sprd,name = "sipx_lte";
        sprd,dst = <0x5>;
        sprd,dl-pool = <0x800>;
        sprd,dl-ack-pool = <0x40>;
        sprd,ul-pool = <0x800>;
        sprd,ul-ack-pool = <0x400>;
    };
    seth@0 {
        compatible = "sprd,seth";
        sprd,dst = <0x5>;
        sprd,channel = <0x7>;
        sprd,blknum = <0x100>;
        phandle = <0x10F>;
    };
    seth@1 {
        compatible = "sprd,seth";
        sprd,dst = <0x5>;
        sprd,channel = <0x8>;
        sprd,blknum = <0x100>;
        phandle = <0x110>;
    };
    seth@2 {
        compatible = "sprd,seth";
        sprd,dst = <0x5>;
        sprd,channel = <0x9>;
        sprd,blknum = <0x100>;
        phandle = <0x111>;
    };
    seth@3 {
        compatible = "sprd,seth";
        sprd,dst = <0x5>;
        sprd,channel = <0x12>;
        sprd,blknum = <0x100>;
        phandle = <0x112>;
    };
    seth@4 {
        compatible = "sprd,seth";
        sprd,dst = <0x5>;
        sprd,channel = <0x13>;
        sprd,blknum = <0x100>;
        phandle = <0x113>;
    };
    seth@5 {
        compatible = "sprd,seth";
        sprd,dst = <0x5>;
        sprd,channel = <0x14>;
        sprd,blknum = <0x100>;
        phandle = <0x114>;
    };
    seth@6 {
        compatible = "sprd,seth";
        sprd,dst = <0x5>;
        sprd,channel = <0x18>;
        sprd,blknum = <0x100>;
        phandle = <0x115>;
    };
    seth@7 {
        compatible = "sprd,seth";
        sprd,dst = <0x5>;
        sprd,channel = <0x19>;
        sprd,blknum = <0x100>;
        phandle = <0x116>;
    };
    seth@8 {
        compatible = "sprd,seth";
        sprd,dst = <0x5>;
        sprd,channel = <0x1A>;
        sprd,blknum = <0x100>;
        phandle = <0x117>;
    };
    seth@9 {
        compatible = "sprd,seth";
        sprd,dst = <0x5>;
        sprd,channel = <0x1B>;
        sprd,blknum = <0x100>;
        phandle = <0x118>;
    };
    seth@10 {
        compatible = "sprd,seth";
        sprd,dst = <0x5>;
        sprd,channel = <0x1C>;
        sprd,blknum = <0x100>;
        phandle = <0x119>;
    };
    seth@11 {
        compatible = "sprd,seth";
        sprd,dst = <0x5>;
        sprd,channel = <0x1D>;
        sprd,blknum = <0x100>;
        phandle = <0x11A>;
    };
    seth@12 {
        compatible = "sprd,seth";
        sprd,dst = <0x5>;
        sprd,channel = <0x1E>;
        sprd,blknum = <0x100>;
        phandle = <0x11B>;
    };
    seth@13 {
        compatible = "sprd,seth";
        sprd,dst = <0x5>;
        sprd,channel = <0x1F>;
        sprd,blknum = <0x100>;
        phandle = <0x11C>;
    };
    sprd-headset {
        compatible = "sprd,headset";
        status = "okay";
        jack-type = <0x0>;
        io-channels = <0x38 0x14>;
        io-channel-names = "headmic_in_little";
        gpios = <0x36 0x3 0x0 0x36 0x8 0x0 0x36 0xC 0x0 0x36 0x5 0x0 0x36 0xD 0x0>;
        gpio-trigger-levels = <0x1 0x1 0x1 0x1 0x1>;
        gpio-dbnc-intervals = <0xA 0x64 0x64 0x64 0x64>;
        gpio-names = "button", "detect_l", "detect_h", "detect_mic", "detect_all";
        adc-threshold-3pole-detect = <0xBEE>;
        sprd,adc-gnd = <0x150>;
        sprd,stable-value = <0x8AF>;
        sprd,coefficient = <0xE573C>;
        irq-threshold-button = <0x9>;
        nvmem-cells = <0x98 0x99 0x9A>;
        nvmem-cell-names = "protectbit", "auxadc", "headmic";
        sprd,spk-route-hp;
        phandle = <0x9B>;
        headset-button@0 {
            adc-min = <0x0>;
            adc-max = <0x1EA>;
            code = <0xE2>;
        };
        headset-button@1 {
            adc-min = <0x21C>;
            adc-max = <0x3FC>;
            code = <0x73>;
        };
        headset-button@2 {
            adc-min = <0x442>;
            adc-max = <0x960>;
            code = <0x72>;
        };
    };
    sound@0 {
        compatible = "sprd,vbc-r1p0v3-codec-sc2721";
        status = "okay";
        sprd-audio-card,name = "sprdphone";
        sprd-audio-card,routing = "HPMIC Pin", "HP Mic Jack", "MIC Pin", "Mic Jack", "MIC2 Pin", "Aux Mic Jack", "HeadPhone Jack", "HP Pin", "Ext Spk", "HP Pin", "Ext Spk1", "HP Pin", "Ext Spk", "SPK Pin", "Ext Spk1", "SPK Pin", "Ext Ear", "EAR Pin", "Ext Ear", "SPK Pin", "Ext Ear", "HP Pin", "DMIC", "DMic Jack", "DMIC1", "DMic1 Jack", "Aud input", "AD Clk", "Aud input1", "AD Clk", "Aud input", "Digital ADCL Switch", "Aud input", "Digital ADCR Switch", "Aud input1", "Digital ADC1L Switch", "Aud input1", "Digital ADC1R Switch";
        sprd-audio-card,headset = <0x9B>;
        sprd-audio-card,fm-open-src = <0x1>;
        sprd-audio-card,fm-hw-rate = <0x7D00>;
        sprd-audio-card,codec-replace-adc-rate = <0xBB80>;
        sprd,spk-ext-pa-info = <0x0 0x0 0x2 0x0>;
        sprd,spk-ext-pa-gpio = <0x9C 0x59 0x0>;
        phandle = <0x11D>;
        sprd-audio-card,dai-link@0 {
            plat {
                sound-dai = <0x9D>;
            };
            cpu {
                sound-dai = <0x9E 0x0>;
            };
            codec {
                sound-dai = <0x9F 0x0>;
            };
        };
        sprd-audio-card,dai-link@1 {
            plat {
                sound-dai = <0x9D>;
            };
            cpu {
                sound-dai = <0xA0 0x0>;
            };
            codec {
                sound-dai = <0x9F 0x1>;
            };
        };
        sprd-audio-card,dai-link@2 {
            plat {
                sound-dai = <0x9D>;
            };
            cpu {
                sound-dai = <0x9E 0x1>;
            };
            codec {
                sound-dai = <0x9F 0x3>;
            };
        };
        sprd-audio-card,dai-link@3 {
            plat {
                sound-dai = <0x9D>;
            };
            cpu {
                sound-dai = <0xA0 0x1>;
            };
            codec {
                sound-dai = <0x9F 0x4>;
            };
        };
        sprd-audio-card,dai-link@4 {
            ops = <0x0>;
            plat {
                sound-dai = <0x9D>;
            };
            cpu {
                sound-dai = <0x9E 0x2>;
            };
            codec {
                sound-dai = <0x9F 0x5>;
            };
        };
        sprd-audio-card,dai-link@5 {
            plat {
                sound-dai = <0x9D>;
            };
            cpu {
                sound-dai = <0x9E 0x3>;
            };
            codec {
                sound-dai = <0x9F 0x6>;
            };
        };
    };
    sound@1 {
        compatible = "sprd,i2s-null-codec";
        status = "okay";
        sprd-audio-card,name = "all-i2s";
        phandle = <0x11E>;
        sprd-audio-card,dai-link@0 {
            plat {
                sound-dai = <0xA1>;
            };
            cpu {
                sound-dai = <0xA2>;
            };
            codec {
                sound-dai = <0x0 0x0>;
            };
        };
    };
    memory {
        device_type = "memory";
        reg = <0x80000000 0x40000000>;
        phandle = <0x11F>;
    };
    firmware {
        android {
            compatible = "android,firmware";
            vbmeta {
                compatible = "android,vbmeta";
                parts = "vbmeta,socko,odmko,boot,dtbo,l_modem,pm_sys,l_ldsp,l_gdsp,vbmeta_hmdodm";
                phandle = <0x120>;
            };
        };
    };
    ion {
        compatible = "sprd,ion";
        #address-cells = <0x1>;
        #size-cells = <0x0>;
        phandle = <0x121>;
    };
    thermal-zones {
        phandle = <0x122>;
        cpu-thmzone {
            polling-delay-passive = <0x64>;
            polling-delay = <0x3E8>;
            sustainable-power = <0xBB8>;
            thermal-sensors = <0xA3 0x0>;
            phandle = <0x123>;
            trips {
                trip-point@0 {
                    temperature = <0x11170>;
                    hysteresis = <0x3E8>;
                    type = "passive";
                    phandle = <0x124>;
                };
                trip-point@1 {
                    temperature = <0x14C08>;
                    hysteresis = <0x3E8>;
                    type = "passive";
                    phandle = <0xA4>;
                };
                bia_crit {
                    temperature = <0x1ADB0>;
                    hysteresis = <0x7D0>;
                    type = "critical";
                    phandle = <0x125>;
                };
            };
            cooling-maps {
                map0 {
                    trip = <0xA4>;
                    contribution = <0x400>;
                    cooling-device = <0xA5 0xFFFFFFFF 0xFFFFFFFF>;
                };
                map1 {
                    trip = <0xA4>;
                    contribution = <0x2A2>;
                    cooling-device = <0xA6 0xFFFFFFFF 0xFFFFFFFF>;
                };
            };
        };
        gpu-thmzone {
            polling-delay-passive = <0x0>;
            polling-delay = <0x0>;
            thermal-sensors = <0xA7 0x0>;
            phandle = <0x126>;
        };
    };
    cooling-devices {
        cluster0-cooling {
            compatible = "sprd,cluster-cooling";
            #cooling-cells = <0x2>;
            sprd,efuse-block7 = <0x7>;
            sprd,efuse-block15 = <0xF>;
            sprd,leak-core = <0x2 0x55 0x74D>;
            sprd,leak-cluster = <0x2 0x55 0x9DC>;
            sprd,core-temp-scale = <0x1D 0xFFFFF7CC 0x186A0 0xFFF72660>;
            sprd,core-voltage-scale = <0xC9 0xFFFFFF57 0x53 0xFFFFFFF0>;
            sprd,cluster-temp-scale = <0x1D 0xFFFFF7CC 0x186A0 0xFFF72660>;
            sprd,cluster-voltage-scale = <0xC9 0xFFFFFF57 0x53 0xFFFFFFF0>;
            sprd,efuse-switch = <0x0>;
            sprd,hotplug-period = <0xA>;
            sprd,min-cpufreq = <0xBB800>;
            sprd,min-cpunum = <0x4>;
            sprd,core-base = <0x960>;
            sprd,cluster-base = <0xF82>;
            sprd,dynamic-core = <0x3EF 0x3E8 0x3E8>;
            sprd,dynamic-cluster = <0x2EB 0x3E8 0x3E8>;
            phandle = <0xA5>;
        };
        cluster1-cooling {
            compatible = "sprd,cluster-cooling";
            #cooling-cells = <0x2>;
            sprd,efuse-block7 = <0x7>;
            sprd,efuse-block15 = <0xF>;
            sprd,leak-core = <0x8 0x55 0x7C0>;
            sprd,leak-cluster = <0x8 0x55 0x810>;
            sprd,core-temp-scale = <0x1D 0xFFFFF7CC 0x186A0 0xFFF72660>;
            sprd,core-voltage-scale = <0xC9 0xFFFFFF57 0x53 0xFFFFFFF0>;
            sprd,cluster-temp-scale = <0x1D 0xFFFFF7CC 0x186A0 0xFFF72660>;
            sprd,cluster-voltage-scale = <0xC9 0xFFFFFF57 0x53 0xFFFFFFF0>;
            sprd,efuse-switch = <0x0>;
            sprd,hotplug-period = <0xA>;
            sprd,min-cpufreq = <0xBB800>;
            sprd,min-cpunum = <0x0>;
            sprd,core-base = <0x105E>;
            sprd,cluster-base = <0xF82>;
            sprd,dynamic-core = <0x600 0x3E8 0x3E8>;
            sprd,dynamic-cluster = <0x2EB 0x3E8 0x3E8>;
            phandle = <0xA6>;
        };
    };
    gpu-cooling-devices {
        gpu-cooling0 {
            compatible = "sprd,mali-power-model";
            #cooling-cells = <0x2>;
            sprd,efuse-block7 = <0x7>;
            sprd,efuse-block15 = <0xF>;
            sprd,leak-core = <0x2 0x55 0x74D>;
            sprd,leak-cluster = <0x2 0x55 0x9DC>;
            sprd,temp-scale = <0x12C 0xFFFF8EB8 0x16C038 0xFF2AF4F0>;
            sprd,voltage-scale = <0xFFFFF9A3 0x19E3 0xFFFFE529 0x8AE>;
            sprd,hotplug-period = <0x0>;
            sprd,core-base = <0x3C6>;
            sprd,cluster-base = <0x3C6>;
            sprd,dynamic-core = <0x179E 0x300 0x384>;
            sprd,dynamic-cluster = <0x17B0 0x300 0x384>;
            phandle = <0x127>;
        };
    };
    display-subsystem {
        compatible = "sprd,display-subsystem";
        ports = <0xA8>;
        gsp = <0xA9>;
    };
    scene-frequency {
        compatible = "sprd,dfs";
        freq-num = <0x8>;
        phandle = <0x128>;
    };
    reserved-memory {
        #address-cells = <0x1>;
        #size-cells = <0x1>;
        ranges;
        phandle = <0x129>;
        warm-boot@0x81ff0000 {
            reg = <0x81FF0000 0x10000>;
            phandle = <0xAB>;
        };
        wcn-mem@84000000 {
            reg = <0x84000000 0x300000>;
            phandle = <0x90>;
        };
        gnss-mem@84300000 {
            reg = <0x84300000 0x15B000>;
            phandle = <0x97>;
        };
        iq-mem@84e00000 {
            compatible = "sprd,iq-mem";
            reg = <0x84E00000 0x4000000>;
            phandle = <0xAA>;
        };
        sipc-mem@88e00000 {
            reg = <0x88E00000 0x800000>;
            phandle = <0x12A>;
        };
        cp-modem@89600000 {
            reg = <0x89600000 0x3E00000>;
            phandle = <0x12B>;
        };
        sml-mem@94000000 {
            reg = <0x94000000 0x40000>;
            phandle = <0x12C>;
        };
        tos-mem@94040000 {
            reg = <0x94040000 0x1FC0000>;
            phandle = <0x12D>;
        };
        logobuffer@9e000000 {
            reg = <0x9E000000 0x7E9000>;
            phandle = <0x3C>;
        };
        ramoops@bff80000 {
            compatible = "ramoops";
            reg = <0xBFF80000 0x40000>;
            record-size = <0x8000>;
            console-size = <0x8000>;
            pmsg-size = <0x8000>;
            phandle = <0x12E>;
        };
    };
    sprd-iq {
        compatible = "sprd,iq";
        sprd,region = <0xAA>;
        sprd,mapping-offs = <0x0>;
    };
    sprd-map-user {
        compatible = "sprd,map-user";
    };
    sprd-wlan {
        compatible = "sprd,sp9863a";
    };
    resume_on_reboot {
        compatible = "sprd,memdisk";
        warm_boot {
            memory-region = <0xAB>;
            label = "warmboot";
        };
    };
    sprd-sensorhub {
        compatible = "sprd,sharkl3-sensorhub";
    };
    autotest {
        compatible = "sprd,autotest";
        sprd,pinctrl = <0xAC>;
        phandle = <0x12F>;
    };
    chosen {
        stdout-path = "/soc/ap-apb/serial@70100000";
        bootargs = "earlycon=sprd_serial,0x70100000,115200n8 console=ttyS1,115200n8 loglevel=1 init=/init root=/dev/ram0 rw printk.devkmsg=on androidboot.boot_devices=soc/soc:ap-ahb/20600000.sdio";
        phandle = <0x130>;
    };
    extcon-gpio {
        compatible = "linux,extcon-usb-gpio";
        vbus-gpio = <0x36 0x0 0x0>;
        id-gpio = <0xAD 0x4 0x0>;
        phandle = <0x11>;
    };
    interrupt-controller {
        compatible = "android,CustomIPI";
        #interrupt-cells = <0x1>;
        interrupt-controller;
        phandle = <0xAE>;
    };
    trusty {
        compatible = "android,trusty-smc-v1";
        irq {
            compatible = "android,trusty-irq-v1";
            interrupt-templates = <0xAE 0x0 0x1 0x1 0x1 0x0 0x1 0x1 0x0 0x0>;
            interrupt-ranges = <0x0 0xF 0x0 0x10 0x1F 0x1 0x20 0xDF 0x2>;
        };
        virtio {
            compatible = "android,trusty-virtio-v1";
        };
        log {
            compatible = "android,trusty-log-v1";
        };
    };
    __symbols__ {
        soc = "/soc";
        modem_dbg_log = "/soc/modem-dbg-log@1000c000";
        ap_ahb_regs = "/soc/syscon@20e00000";
        pub_apb_regs = "/soc/syscon@300e0000";
        pub_ahb_regs = "/soc/syscon@300f0000";
        aon_mailbox = "/soc/mailbox@400a0000";
        aon_intc_regs = "/soc/syscon@40200000";
        pmu_apb_regs = "/soc/syscon@402b0000";
        disp_pd = "/soc/power-domain@402b0058";
        aon_apb_regs = "/soc/syscon@402e0000";
        anlg_phy_g1_regs = "/soc/syscon@40350000";
        anlg_phy_g2_regs = "/soc/syscon@40353000";
        anlg_phy_g4_regs = "/soc/syscon@40359000";
        anlg_phy_g5_regs = "/soc/syscon@4035c000";
        anlg_phy_g7_regs = "/soc/syscon@40363000";
        anlg_wrap_wcn_regs = "/soc/syscon@40366000";
        wcn_regs = "/soc/syscon@403a0000";
        mm_ahb_regs = "/soc/syscon@60800000";
        mm_vsp_ahb_regs = "/soc/syscon@62000000";
        ap_apb_regs = "/soc/syscon@71300000";
        ap_intc0_regs = "/soc/syscon@40500000";
        ap_intc1_regs = "/soc/syscon@40510000";
        ap_intc2_regs = "/soc/syscon@40520000";
        ap_intc3_regs = "/soc/syscon@40530000";
        ap_intc4_regs = "/soc/syscon@40540000";
        ap_intc5_regs = "/soc/syscon@40550000";
        uart0 = "/soc/ap-apb/serial@70000000";
        uart1 = "/soc/ap-apb/serial@70100000";
        uart2 = "/soc/ap-apb/serial@70200000";
        uart3 = "/soc/ap-apb/serial@70300000";
        uart4 = "/soc/ap-apb/serial@70400000";
        i2c0 = "/soc/ap-apb/i2c@70500000";
        i2c1 = "/soc/ap-apb/i2c@70600000";
        i2c2 = "/soc/ap-apb/i2c@70700000";
        i2c3 = "/soc/ap-apb/i2c@70800000";
        i2c4 = "/soc/ap-apb/i2c@70900000";
        spi0 = "/soc/ap-apb/spi@70a00000";
        spi1 = "/soc/ap-apb/spi@70b00000";
        spi2 = "/soc/ap-apb/spi@70c00000";
        i2s0 = "/soc/ap-apb/i2s@70d00000";
        spi3 = "/soc/ap-apb/spi@71400000";
        i2c5 = "/soc/ap-apb/i2c@71500000";
        i2c6 = "/soc/ap-apb/i2c@71600000";
        ap_dma = "/soc/ap-ahb/dma-controller@20100000";
        usb = "/soc/ap-ahb/usb@20200000";
        hsphy = "/soc/ap-ahb/hsphy@20e00000";
        sdio3 = "/soc/ap-ahb/sdio@20600000";
        sdio0 = "/soc/ap-ahb/sdio@20300000";
        sprd_audio_codec_dig = "/soc/aon/audio-codec@40000000";
        vbc = "/soc/aon/vbc@40020000";
        aon_dma = "/soc/aon/dma-controller@40100000";
        eic_debounce = "/soc/aon/gpio@40210000";
        eic_latch = "/soc/aon/gpio@40210080";
        eic_async = "/soc/aon/gpio@402100a0";
        eic_sync = "/soc/aon/gpio@402100c0";
        aon_sysfrt = "/soc/aon/timer@40040000";
        aon_systimer = "/soc/aon/timer@40230000";
        ap_efuse = "/soc/aon/efuse@40240000";
        gthm_delta = "/soc/aon/efuse@40240000/gthm-delta@21";
        cthm_sign = "/soc/aon/efuse@40240000/cthm-sign@22";
        cthm_ratio = "/soc/aon/efuse@40240000/cthm-ratio@22";
        cthm_delta = "/soc/aon/efuse@40240000/cthm-delta@23";
        wcn_alpha = "/soc/aon/efuse@40240000/wcn-alpha@14";
        wcn_beta = "/soc/aon/efuse@40240000/wcn-beta@18";
        wcn_gamma = "/soc/aon/efuse@40240000/wcn-gamma@1c";
        wcn_delta = "/soc/aon/efuse@40240000/wcn-delta@20";
        dvfs_bin_dsu = "/soc/aon/efuse@40240000/dvfs-bin-dsu@a";
        dvfs_bin_cpu0 = "/soc/aon/efuse@40240000/dvfs-bin-cpu0@9";
        dvfs_bin_cpu1 = "/soc/aon/efuse@40240000/dvfs-bin-cpu1@9";
        pwms = "/soc/aon/pwm@40260000";
        pin_controller = "/soc/aon/pinctrl@402a0000";
        vbc_iis1_0 = "/soc/aon/pinctrl@402a0000/iismtx-inf0-8";
        ap_iis0_0 = "/soc/aon/pinctrl@402a0000/iismtx-inf0-0";
        ap_iis1_0 = "/soc/aon/pinctrl@402a0000/iismtx-inf0-1";
        tgdsp_iis0_0 = "/soc/aon/pinctrl@402a0000/iismtx-inf0-4";
        tgdsp_iis1_0 = "/soc/aon/pinctrl@402a0000/iismtx-inf0-5";
        pubcp_iis0_0 = "/soc/aon/pinctrl@402a0000/iismtx-inf0-3";
        vbc_iis1_3 = "/soc/aon/pinctrl@402a0000/iismtx-inf3-8";
        ap_iis0_3 = "/soc/aon/pinctrl@402a0000/iismtx-inf3-0";
        tgdsp_iis0_3 = "/soc/aon/pinctrl@402a0000/iismtx-inf3-4";
        tgdsp_iis1_3 = "/soc/aon/pinctrl@402a0000/iismtx-inf3-5";
        pubcp_iis0_3 = "/soc/aon/pinctrl@402a0000/iismtx-inf3-3";
        wcn_iis0_3 = "/soc/aon/pinctrl@402a0000/iismtx-inf3-11";
        vbc_iis1_4 = "/soc/aon/pinctrl@402a0000/iismtx-inf4-8";
        ap_iis0_4 = "/soc/aon/pinctrl@402a0000/iismtx-inf4-0";
        tgdsp_iis0_4 = "/soc/aon/pinctrl@402a0000/iismtx-inf4-4";
        tgdsp_iis1_4 = "/soc/aon/pinctrl@402a0000/iismtx-inf4-5";
        pubcp_iis0_4 = "/soc/aon/pinctrl@402a0000/iismtx-inf4-3";
        wcn_iis0_4 = "/soc/aon/pinctrl@402a0000/iismtx-inf4-11";
        iis_loop_3_4_enable = "/soc/aon/pinctrl@402a0000/iismtx-inf3-inf4-loop-1";
        iis_loop_3_4_disable = "/soc/aon/pinctrl@402a0000/iismtx-inf3-inf4-loop-0";
        ap_gpio = "/soc/aon/gpio-controller@402c0000";
        gpu_thm = "/soc/aon/gpu-thm@402f0000";
        cpu_thm = "/soc/aon/cpu-thm@40390000";
        hwlock = "/soc/aon/hwspinlock@40060000";
        i2c7 = "/soc/aon/i2c@40080000";
        fan53555_dcdc = "/soc/aon/i2c@40080000/regulator@60";
        sprd_hwdvfs = "/soc/aon/hwdvfs@40300000";
        sprd_swdvfs = "/soc/aon/sprd-swdvfs";
        djtag = "/soc/aon/djtag@40340000";
        adi_bus = "/soc/aon/spi@41800000";
        sc2721_pmic = "/soc/aon/spi@41800000/pmic@0";
        pmic_wdt = "/soc/aon/spi@41800000/pmic@0/watchdog@40";
        pmic_eic = "/soc/aon/spi@41800000/pmic@0/gpio-controller@280";
        pmic_flash = "/soc/aon/spi@41800000/pmic@0/flash@2a8";
        fgu_calib = "/soc/aon/spi@41800000/pmic@0/efuse@300/calib@6";
        adc_bcal = "/soc/aon/spi@41800000/pmic@0/efuse@300/calib@24";
        adc_scal = "/soc/aon/spi@41800000/pmic@0/efuse@300/calib@26";
        cc_cal = "/soc/aon/spi@41800000/pmic@0/efuse@300/calib@1a";
        efuse_blk0 = "/soc/aon/spi@41800000/pmic@0/efuse@300/calib@0";
        efuse_blk14 = "/soc/aon/spi@41800000/pmic@0/efuse@300/calib@28";
        efuse_blk16 = "/soc/aon/spi@41800000/pmic@0/efuse@300/calib@2c";
        pmic_typec = "/soc/aon/spi@41800000/pmic@0/typec@380";
        pmic_adc = "/soc/aon/spi@41800000/pmic@0/adc@400";
        pmic_fgu = "/soc/aon/spi@41800000/pmic@0/fgu@a00";
        sprd_audio_codec_ana = "/soc/aon/spi@41800000/pmic@0/audio-codec@700";
        vddcpu = "/soc/aon/spi@41800000/pmic@0/power-controller@c00/DCDC_CPU";
        vddcore = "/soc/aon/spi@41800000/pmic@0/power-controller@c00/DCDC_CORE";
        vddmem = "/soc/aon/spi@41800000/pmic@0/power-controller@c00/DCDC_MEM";
        vddgen = "/soc/aon/spi@41800000/pmic@0/power-controller@c00/DCDC_GEN";
        vddcama = "/soc/aon/spi@41800000/pmic@0/power-controller@c00/LDO_VDDCAMA";
        vddcammot = "/soc/aon/spi@41800000/pmic@0/power-controller@c00/LDO_VDDCAMMOT";
        vddsim2 = "/soc/aon/spi@41800000/pmic@0/power-controller@c00/LDO_VDDSIM2";
        vddemmccore = "/soc/aon/spi@41800000/pmic@0/power-controller@c00/LDO_VDDEMMCCORE";
        vddsdcore = "/soc/aon/spi@41800000/pmic@0/power-controller@c00/LDO_VDDSDCORE";
        vddsdio = "/soc/aon/spi@41800000/pmic@0/power-controller@c00/LDO_VDDSDIO";
        vdd28 = "/soc/aon/spi@41800000/pmic@0/power-controller@c00/LDO_VDD28";
        vddwifipa = "/soc/aon/spi@41800000/pmic@0/power-controller@c00/LDO_VDDWIFIPA";
        vdd18_dcxo = "/soc/aon/spi@41800000/pmic@0/power-controller@c00/LDO_VDD18_DCXO";
        vddusb33 = "/soc/aon/spi@41800000/pmic@0/power-controller@c00/LDO_VDDUSB33";
        vddcamd = "/soc/aon/spi@41800000/pmic@0/power-controller@c00/LDO_VDDCAMD";
        vddcon = "/soc/aon/spi@41800000/pmic@0/power-controller@c00/LDO_VDDCON";
        vddcamio = "/soc/aon/spi@41800000/pmic@0/power-controller@c00/LDO_VDDCAMIO";
        vdd18 = "/soc/aon/spi@41800000/pmic@0/power-controller@c00/LDO_VDD18";
        vddrf18 = "/soc/aon/spi@41800000/pmic@0/power-controller@c00/LDO_VDDRF18";
        vddrf125 = "/soc/aon/spi@41800000/pmic@0/power-controller@c00/LDO_VDDRF125";
        vddldomem = "/soc/aon/spi@41800000/pmic@0/power-controller@c00/LDO_VDDLDOMEM";
        vddkpled = "/soc/aon/spi@41800000/pmic@0/power-controller@c00/LDO_VDDKPLED";
        cam_domain = "/soc/mm/cam-domain";
        gpu = "/soc/mm/gpu@60000000";
        dpu = "/soc/mm/dpu@63000000";
        dpu_port = "/soc/mm/dpu@63000000/port";
        dpu_out = "/soc/mm/dpu@63000000/port/endpoint";
        gsp_core0 = "/soc/mm/gsp@63000000";
        iommu_dispc = "/soc/mm/iommu@63000800";
        vsp = "/soc/mm/video-codec@62200000";
        iommu_vsp = "/soc/mm/iommu@62200000";
        jpg = "/soc/mm/jpeg-codec@62300000";
        iommu_jpg = "/soc/mm/iommu@62300300";
        dsi = "/soc/mm/dsi@63100000";
        dsi_out = "/soc/mm/dsi@63100000/ports/port@0/endpoint";
        dsi_in = "/soc/mm/dsi@63100000/ports/port@1/endpoint";
        panel = "/soc/mm/dsi@63100000/panel";
        panel_in = "/soc/mm/dsi@63100000/panel/port@1/endpoint";
        dphy = "/soc/mm/dphy";
        dphy_out = "/soc/mm/dphy/port@0/endpoint";
        dphy_in = "/soc/mm/dphy/port@1/endpoint";
        mipi_csi_phy0 = "/soc/mm/mipi-csi-phy0";
        mipi_csi_phy1 = "/soc/mm/mipi-csi-phy1";
        mipi_csi_phy2 = "/soc/mm/mipi-csi-phy2";
        mipi_csi_phy0_m = "/soc/mm/mipi-csi-phy0-s";
        mipi_csi_phy0_s = "/soc/mm/mipi-csi-phy0-m";
        mipi_csi_phy0_s1 = "/soc/mm/mipi-csi-phy0-m1";
        dcam = "/soc/mm/dcam@60a00000";
        iommu_dcam = "/soc/mm/iommu@60a0c000";
        isp = "/soc/mm/isp@60b00000";
        iommu_isp = "/soc/mm/iommu@60bffc00";
        csi0 = "/soc/mm/csi@60c00000";
        csi1 = "/soc/mm/csi@60d00000";
        csi2 = "/soc/mm/csi@60e00000";
        cpp = "/soc/mm/cpp@62400000";
        iommu_cpp = "/soc/mm/iommu@62400200";
        dmc_controller = "/soc/pub/dmc-controller@30000000";
        ptm_trace = "/soc/pub/ptm@30010000";
        dmc_mpu = "/soc/pub/dmc-mpu@300e0000";
        pmu_gate = "/soc/pmu-gate";
        pll = "/soc/pll";
        mpll = "/soc/mpll";
        rpll = "/soc/rpll";
        dpll = "/soc/dpll";
        ap_clk = "/soc/clock-controller@21500000";
        aon_clk = "/soc/clock-controller@402d0000";
        apahb_gate = "/soc/apahb-gate";
        aonapb_gate = "/soc/aonapb-gate";
        mm_gate = "/soc/mm-gate";
        mm_clk = "/soc/clock-controller@60900000";
        vspahb_gate = "/soc/vspahb-gate";
        apapb_gate = "/soc/apapb-gate";
        funnel_soc_out_port0 = "/soc/funnel@10001000/ports/port@0/endpoint";
        funnel_soc_in_port0 = "/soc/funnel@10001000/ports/port@1/endpoint";
        etb_in = "/soc/etb@10003000/port/endpoint";
        funnel_little_out_port0 = "/soc/funnel@12001000/ports/port@0/endpoint";
        funnel_little_in_port0 = "/soc/funnel@12001000/ports/port@1/endpoint";
        funnel_little_in_port1 = "/soc/funnel@12001000/ports/port@2/endpoint";
        funnel_little_in_port2 = "/soc/funnel@12001000/ports/port@3/endpoint";
        funnel_little_in_port3 = "/soc/funnel@12001000/ports/port@4/endpoint";
        etf_little_out = "/soc/etf@12002000/port@0/endpoint";
        etf_little_in = "/soc/etf@12002000/port@1/endpoint";
        etf_big_out = "/soc/etf@12003000/port@0/endpoint";
        etf_big_in = "/soc/etf@12003000/port@1/endpoint";
        funnel_ca55_out_port0 = "/soc/funnel@12004000/ports/port@0/endpoint";
        funnel_ca55_in_port0 = "/soc/funnel@12004000/ports/port@1/endpoint";
        funnel_ca55_in_port1 = "/soc/funnel@12004000/ports/port@2/endpoint";
        funnel_big_out_port0 = "/soc/funnel@12005000/ports/port@0/endpoint";
        funnel_big_in_port0 = "/soc/funnel@12005000/ports/port@1/endpoint";
        funnel_big_in_port1 = "/soc/funnel@12005000/ports/port@2/endpoint";
        funnel_big_in_port2 = "/soc/funnel@12005000/ports/port@3/endpoint";
        funnel_big_in_port3 = "/soc/funnel@12005000/ports/port@4/endpoint";
        etm0_out = "/soc/etm@13040000/port/endpoint";
        etm1_out = "/soc/etm@13140000/port/endpoint";
        etm2_out = "/soc/etm@13240000/port/endpoint";
        etm3_out = "/soc/etm@13340000/port/endpoint";
        etm4_out = "/soc/etm@13440000/port/endpoint";
        etm5_out = "/soc/etm@13540000/port/endpoint";
        etm6_out = "/soc/etm@13640000/port/endpoint";
        etm7_out = "/soc/etm@13740000/port/endpoint";
        ext_26m = "/ext-26m";
        ext_13m = "/ext-13m";
        ext_6m5 = "/ext-6m5";
        ext_4m3 = "/ext-4m3";
        ext_4m = "/ext-4m";
        ext_250k = "/ext-250k";
        ext_32k = "/ext-32k";
        ext_1m = "/ext-1m";
        ext_2m = "/ext-2m";
        ext_rc0_4m = "/ext-rc0-4m";
        clk_pad = "/clk-pad";
        rco_100m = "/rco-100m";
        sprd_pcm = "/sprd-pcm-audio";
        vaudio = "/vaudio";
        sprd_pcm_iis = "/sprd-pcm-iis";
        CPU0 = "/cpus/cpu@0";
        CPU1 = "/cpus/cpu@100";
        CPU2 = "/cpus/cpu@200";
        CPU3 = "/cpus/cpu@300";
        CPU4 = "/cpus/cpu@400";
        CPU5 = "/cpus/cpu@500";
        CPU6 = "/cpus/cpu@600";
        CPU7 = "/cpus/cpu@700";
        CPU_COST_0 = "/energy-costs/core-cost0";
        CPU_COST_1 = "/energy-costs/core-cost1";
        CLUSTER_COST_0 = "/energy-costs/cluster-cost0";
        CLUSTER_COST_1 = "/energy-costs/cluster-cost1";
        CORE_PD = "/idle-states/core_pd";
        cpufreq_clus0 = "/cpufreq-clus0";
        cpufreq_clus1 = "/cpufreq-clus1";
        cpufreq_fcm = "/cpufreq-fcm";
        gic = "/interrupt-controller@14000000";
        v2m_0 = "/interrupt-controller@14000000/v2m@0";
        power = "/power-debug";
        gsp = "/sprd-gsp";
        wcn_btwf = "/cpwcn_btwf";
        wcn_gnss = "/cpwcn_gnss";
        sipc2 = "/wcn_sipc/sipc@84180000";
        sipc3 = "/wcn_sipc/sipc@8441b000";
        scproc_pubpm = "/scproc-pubcp/scproc@800000";
        scproc_pubcp = "/scproc-pubcp/scproc@f000";
        sipc0 = "/sprd-sipc/sipc@88e00000";
        sipc1 = "/sprd-sipc/sipc@d000";
        seth_ch7 = "/seth@0";
        seth_ch8 = "/seth@1";
        seth_ch9 = "/seth@2";
        seth_ch18 = "/seth@3";
        seth_ch19 = "/seth@4";
        seth_ch20 = "/seth@5";
        seth_ch24 = "/seth@6";
        seth_ch25 = "/seth@7";
        seth_ch26 = "/seth@8";
        seth_ch27 = "/seth@9";
        seth_ch28 = "/seth@10";
        seth_ch29 = "/seth@11";
        seth_ch30 = "/seth@12";
        seth_ch31 = "/seth@13";
        sprd_headset = "/sprd-headset";
        sound_vbc_r1p0v3_sprd_codec = "/sound@0";
        sound_sprd_ap_alliis = "/sound@1";
        memory = "/memory";
        vbmeta = "/firmware/android/vbmeta";
        ion = "/ion";
        thm_zone = "/thermal-zones";
        cpu_thmzone = "/thermal-zones/cpu-thmzone";
        cpu_threshold = "/thermal-zones/cpu-thmzone/trips/trip-point@0";
        cpu_target = "/thermal-zones/cpu-thmzone/trips/trip-point@1";
        cpu_crit = "/thermal-zones/cpu-thmzone/trips/bia_crit";
        gpu_thmzone = "/thermal-zones/gpu-thmzone";
        cluster0_cooling = "/cooling-devices/cluster0-cooling";
        cluster1_cooling = "/cooling-devices/cluster1-cooling";
        gpu_cooling0 = "/gpu-cooling-devices/gpu-cooling0";
        ddr_dfs = "/scene-frequency";
        reserved_memory = "/reserved-memory";
        warm_boot_reserved = "/reserved-memory/warm-boot@0x81ff0000";
        wcn_reserved = "/reserved-memory/wcn-mem@84000000";
        gnss_reserved = "/reserved-memory/gnss-mem@84300000";
        iq_reserved = "/reserved-memory/iq-mem@84e00000";
        smem_reserved = "/reserved-memory/sipc-mem@88e00000";
        cp_reserved = "/reserved-memory/cp-modem@89600000";
        sml_reserved = "/reserved-memory/sml-mem@94000000";
        tos_reserved = "/reserved-memory/tos-mem@94040000";
        logo_reserved = "/reserved-memory/logobuffer@9e000000";
        pstore_reserved = "/reserved-memory/ramoops@bff80000";
        autotest = "/autotest";
        chosen = "/chosen";
        extcon_gpio = "/extcon-gpio";
        ipi = "/interrupt-controller";
    };
};
